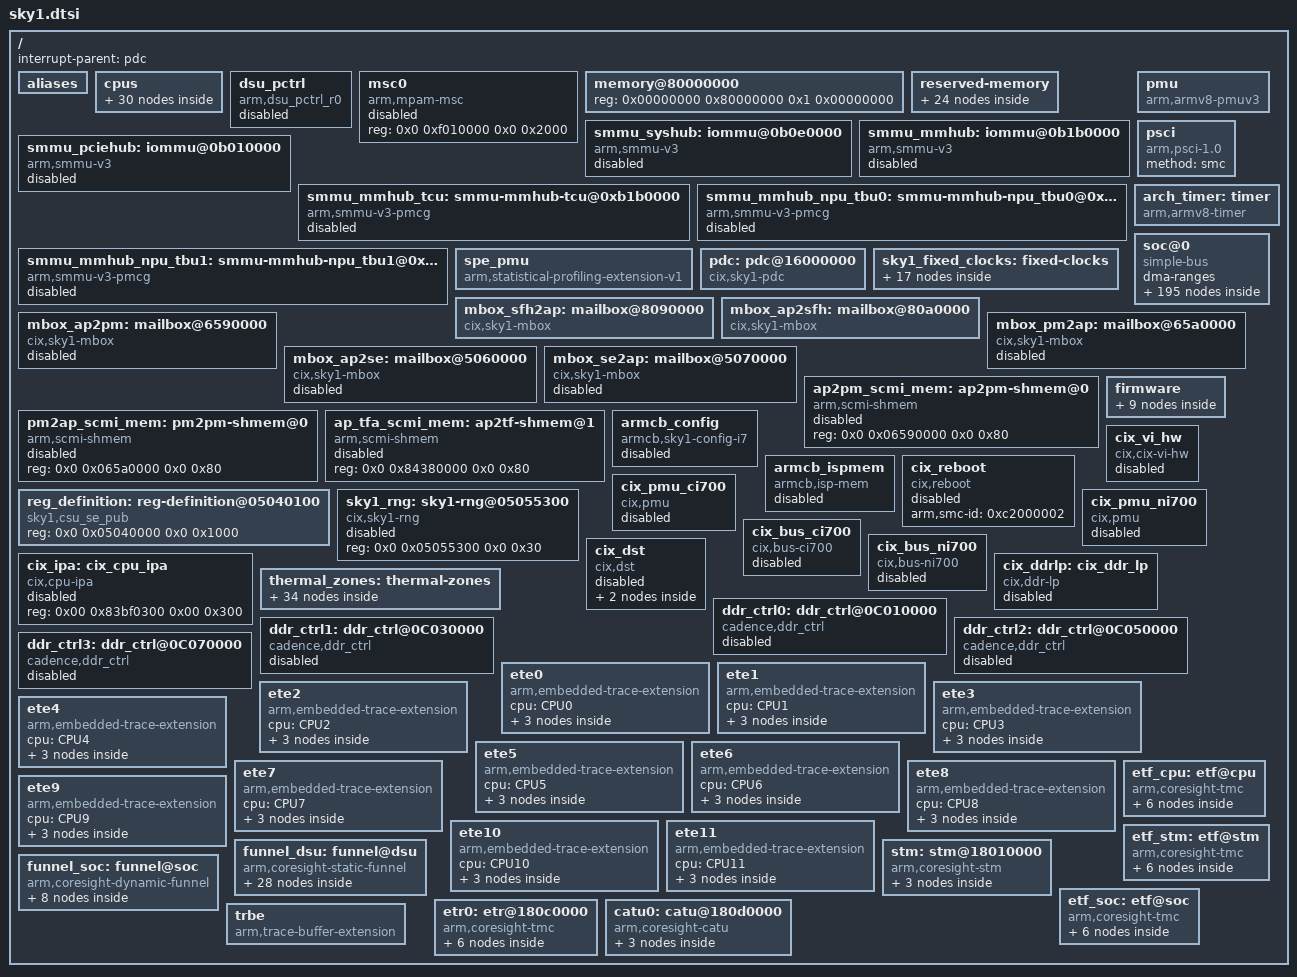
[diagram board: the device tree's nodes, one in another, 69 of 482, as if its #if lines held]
/*
 * Copyright 2024 Cix Technology Group Co., Ltd.
 *
 * SPDX-License-Identifier: BSD-3-Clause
 */

#include <dt-bindings/interrupt-controller/arm-gic.h>
#include <dt-bindings/clock/sky1-audss.h>
#include <dt-bindings/phy/phy.h>
#include <dt-bindings/phy/phy-cadence-torrent.h>
#include <dt-bindings/thermal/thermal.h>
#include <dt-bindings/power/sky1-power.h>
#include <dt-bindings/reset/sky1-reset.h>
#include <dt-bindings/clock/sky1-clk.h>
#include <dt-bindings/thermal/sky1-thermal.h>
#include <dt-bindings/reset/sky1-reset-fch.h>
#include <dt-bindings/reset/sky1-reset-audss.h>
#include <dt-bindings/gpio/gpio.h>
#include <dt-bindings/pinctrl/pads-sky1.h>

/memreserve/ 0x80000000 0x6000000;

/ {
	interrupt-parent = <&pdc>;
	#address-cells = <2>;
	#size-cells = <2>;

	aliases {
		serial0 = &uart0;
		serial1 = &uart1;
		serial2 = &uart2;
		serial3 = &uart3;
		serial4 = &uart4;
		serial5 = &uart5;
		cix-bridge0 = &cix_bridge_0;
		cix-bridge1 = &cix_bridge_1;
		cix-bridge2 = &cix_bridge_2;
		cix-bridge3 = &cix_bridge_3;
		cix-csi0 = &cix_mipi_csi_0;
		cix-csi1 = &cix_mipi_csi_1;
		cix-csi2 = &cix_mipi_csi_2;
		cix-csi3 = &cix_mipi_csi_3;
		cix-dphy0 = &cix_dphy_0;
		cix-dphy1 = &cix_dphy_1;
		cix-dphy2 = &cix_dphy_2;
		cix-dphy3 = &cix_dphy_3;
		cix-dphy4 = &cix_dphy_4;
		cix-dphy5 = &cix_dphy_5;
		cix-dphy-hw0 = &cix_dphy_hw_0;
		cix-dphy-hw1 = &cix_dphy_hw_1;
		pcie_rc0 = &pcie_x8_rc;
		pcie_rc1 = &pcie_x4_rc;
		pcie_rc2 = &pcie_x2_rc;
		pcie_rc3 = &pcie_x1_1_rc;
		pcie_rc4 = &pcie_x1_0_rc;
		i2s0 = &i2s0;
		i2s1 = &i2s1;
		i2s2 = &i2s2;
		i2s3 = &i2s3;
		i2s4 = &i2s4;
		i2s5 = &i2s5;
		i2s6 = &i2s6;
		i2s7 = &i2s7;
		i2s8 = &i2s8;
		i2s9 = &i2s9;
		usb0 = &sky1_usbss_0;
		usb1 = &sky1_usbss_1;
		usb2 = &sky1_usbss_2;
		usb3 = &sky1_usbss_3;
		usb4 = &sky1_usbss_4;
		usb5 = &sky1_usbss_5;
		usb6 = &sky1_usbhs_0;
		usb7 = &sky1_usbhs_1;
		usb8 = &sky1_usbhs_2;
		usb9 = &sky1_usbhs_3;
		usbdpphy0 = &usbc_phy0;
		usbdpphy1 = &usbc_phy1;
		usbdpphy2 = &usbc_phy2;
		usbdpphy3 = &usbc_phy3;
		i2c0 = &i2c0;
		i2c1 = &i2c1;
		i2c2 = &i2c2;
		i2c3 = &i2c3;
		i2c4 = &i2c4;
		i2c5 = &i2c5;
		i2c6 = &i2c6;
		i2c7 = &i2c7;
		i2c8 = &sf_i2c0;
		i2c9 = &sf_i2c1;
		i2c10 = &i2c2_slave;
		i3c0 = &i3c0;
		i3c1 = &i3c1;
		i3c2 = &sf_i3c0;
		i3c3 = &sf_i3c1;
		spi0 = &spi0;
		spi1 = &spi1;
		spi2 = &sf_spi;
		gpio0 = &s5_gpio0;
		gpio1 = &s5_gpio1;
		gpio2 = &s5_gpio2;
		gpio3 = &fch_gpio0;
		gpio4 = &fch_gpio1;
		gpio5 = &fch_gpio2;
		gpio6 = &fch_gpio3;
		linlondp0 = &dpu0;
		linlondp1 = &dpu1;
		linlondp2 = &dpu2;
		linlondp3 = &dpu3;
		linlondp4 = &dpu4;
	};

	cpus {
		#address-cells = <2>;
		#size-cells = <0>;

		cpu-map {
			cluster0 {
				core0 {
					cpu = <&CPU0>;
				};
				core1 {
					cpu = <&CPU1>;
				};
				core2 {
					cpu = <&CPU2>;
				};
				core3 {
					cpu = <&CPU3>;
				};
				core4 {
					cpu = <&CPU4>;
				};
				core5 {
					cpu = <&CPU5>;
				};
				core6 {
					cpu = <&CPU6>;
				};
				core7 {
					cpu = <&CPU7>;
				};
				core8 {
					cpu = <&CPU8>;
				};
				core9 {
					cpu = <&CPU9>;
				};
				core10 {
					cpu = <&CPU10>;
				};
				core11 {
					cpu = <&CPU11>;
				};
			};
		};

		idle-states {
			CPU_SLEEP_0: cpu-sleep-0 {
				compatible = "arm,idle-state";
				arm,psci-suspend-param = <0x0010000>;
				local-timer-stop;
				entry-latency-us = <34>;
				exit-latency-us = <100>;
				min-residency-us = <3000>;
			};

			CPU_SLEEP_1: cpu-sleep-1 {
				compatible = "arm,idle-state";
				arm,psci-suspend-param = <0x10000>;
				local-timer-stop;
				entry-latency-us = <31>;
				exit-latency-us = <79>;
				min-residency-us = <3000>;
			};

			CLUSTER_SLEEP_0: cluster-sleep-0 {
				compatible = "arm,idle-state";
				arm,psci-suspend-param = <0x1010000>;
				local-timer-stop;
				entry-latency-us = <41>;
				exit-latency-us = <104>;
				min-residency-us = <4000>;
			};
		};

		CPU0: cpu0@0 {
			compatible = "arm,armv8";
			reg = <0x0 0x0>;
			device_type = "cpu";
			enable-method = "psci";
			clocks = <&scmi_dvfs 2>;
			#cooling-cells = <2>;
			cpu-idle-states = <&CPU_SLEEP_0 &CLUSTER_SLEEP_0>;
			capacity-dmips-mhz = <403>;
		};

		CPU1: cpu1@100 {
			compatible = "arm,armv8";
			reg = <0x0 0x100>;
			device_type = "cpu";
			enable-method = "psci";
			clocks = <&scmi_dvfs 2>;
			#cooling-cells = <2>;
			cpu-idle-states = <&CPU_SLEEP_0 &CLUSTER_SLEEP_0>;
			capacity-dmips-mhz = <403>;
		};

		CPU2: cpu2@200 {
			compatible = "arm,armv8";
			reg = <0x0 0x200>;
			device_type = "cpu";
			enable-method = "psci";
			clocks = <&scmi_dvfs 2>;
			#cooling-cells = <2>;
			cpu-idle-states = <&CPU_SLEEP_0 &CLUSTER_SLEEP_0>;
			capacity-dmips-mhz = <403>;
		};

		CPU3: cpu3@300 {
			compatible = "arm,armv8";
			reg = <0x0 0x300>;
			device_type = "cpu";
			enable-method = "psci";
			clocks = <&scmi_dvfs 2>;
			#cooling-cells = <2>;
			cpu-idle-states = <&CPU_SLEEP_0 &CLUSTER_SLEEP_0>;
			capacity-dmips-mhz = <403>;
		};

		CPU4: cpu4@400 {
			compatible = "arm,armv8";
			reg = <0x0 0x400>;
			device_type = "cpu";
			enable-method = "psci";
			clocks = <&scmi_dvfs 5>;
			#cooling-cells = <2>;
			cpu-idle-states = <&CPU_SLEEP_1 &CLUSTER_SLEEP_0>;
			capacity-dmips-mhz = <1024>;
		};

		CPU5: cpu5@500 {
			compatible = "arm,armv8";
			reg = <0x0 0x500>;
			device_type = "cpu";
			enable-method = "psci";
			clocks = <&scmi_dvfs 5>;
			#cooling-cells = <2>;
			cpu-idle-states = <&CPU_SLEEP_1 &CLUSTER_SLEEP_0>;
			capacity-dmips-mhz = <1024>;
		};

		CPU6: cpu6@600 {
			compatible = "arm,armv8";
			reg = <0x0 0x600>;
			device_type = "cpu";
			enable-method = "psci";
			clocks = <&scmi_dvfs 6>;
			#cooling-cells = <2>;
			cpu-idle-states = <&CPU_SLEEP_1 &CLUSTER_SLEEP_0>;
			capacity-dmips-mhz = <1024>;
		};

		CPU7: cpu7@700 {
			compatible = "arm,armv8";
			reg = <0x0 0x700>;
			device_type = "cpu";
			enable-method = "psci";
			clocks = <&scmi_dvfs 6>;
			#cooling-cells = <2>;
			cpu-idle-states = <&CPU_SLEEP_1 &CLUSTER_SLEEP_0>;
			capacity-dmips-mhz = <1024>;
		};

		CPU8: cpu8@800 {
			compatible = "arm,armv8";
			reg = <0x0 0x800>;
			device_type = "cpu";
			enable-method = "psci";
			clocks = <&scmi_dvfs 3>;
			#cooling-cells = <2>;
			cpu-idle-states = <&CPU_SLEEP_1 &CLUSTER_SLEEP_0>;
			capacity-dmips-mhz = <1024>;
		};

		CPU9: cpu9@900 {
			compatible = "arm,armv8";
			reg = <0x0 0x900>;
			device_type = "cpu";
			enable-method = "psci";
			clocks = <&scmi_dvfs 3>;
			#cooling-cells = <2>;
			cpu-idle-states = <&CPU_SLEEP_1 &CLUSTER_SLEEP_0>;
			capacity-dmips-mhz = <1024>;
		};

		CPU10: cpu10@a00 {
			compatible = "arm,armv8";
			reg = <0x0 0xa00>;
			device_type = "cpu";
			enable-method = "psci";
			clocks = <&scmi_dvfs 4>;
			#cooling-cells = <2>;
			cpu-idle-states = <&CPU_SLEEP_1 &CLUSTER_SLEEP_0>;
			capacity-dmips-mhz = <1024>;
		};

		CPU11: cpu11@b00 {
			compatible = "arm,armv8";
			reg = <0x0 0xb00>;
			device_type = "cpu";
			enable-method = "psci";
			clocks = <&scmi_dvfs 4>;
			#cooling-cells = <2>;
			cpu-idle-states = <&CPU_SLEEP_1 &CLUSTER_SLEEP_0>;
			capacity-dmips-mhz = <1024>;
		};
	};

	dsu_pctrl: dsu_pctrl {
		compatible = "arm,dsu_pctrl_r0";
		size = <8192>; /* size in KB */
		line-size = <64>;
		static-leakage-per-mb = <10000>; /*uW/MB */
		dram-energy-per-mb = <130>; /* uJ/MB */
		polling = <10000>; /* miliseconds */
		/* hw-automatic-control; */
		/* cluster-l3-dn-th0 = <100>; */
		/* cluster-l3-dn-th1 = <200>; */
		/* cluster-l3-up-th0 = <300>; */
		/* cluster-l3-up-th1 = <400>; */
		/* cluster-l3-up-th2 = <500>; */
		/* cluster-l3-auto-interval = <5>; */ /* IMP_CLUSTERPWRCTLR_EL1.AUTOPRTN */
		status = "disabled";
	};

	/*
	 * L3 cache in the DSU is the Memory System Component (MSC)
	 * The MPAM registers are accessed through utility bus in the DSU
	 */
	msc0 {
		compatible = "arm,mpam-msc";
		reg = <0x0 0xf010000 0x0 0x2000>;
		status = "disabled";
	};

	memory@80000000 {
		#address-cells = <2>;
		#size-cells = <2>;
		device_type = "memory";
		reg = <0x00000000 0x80000000 0x1 0x00000000>;
	};

	reserved-memory {
		#address-cells = <2>;
		#size-cells = <2>;
		ranges;

		linux,cma {
			compatible = "shared-dma-pool";
			reusable;
			size = <0x0 0x28000000>;
			linux,cma-default;
		};

		dpu_gop: dpu_gop@84800000 {
			reg = <0x0 0x84800000 0x0 0x2000000>;
			iommu-addresses = <&dpu0 0x0 0x84800000 0x0 0x02000000>,
				<&dpu1 0x0 0x84800000 0x0 0x02000000>,
				<&dpu2 0x0 0x84800000 0x0 0x02000000>,
				<&dpu3 0x0 0x84800000 0x0 0x02000000>,
				<&dpu4 0x0 0x84800000 0x0 0x02000000>;
			status = "disabled"; /* not for device dma and cma memory */
			no-map;
		};

		smc_shmem_reserved: smc_shmem@84380000 {
			reg = <0x0 0x84380000 0x0 0x80000>;
			no-map;
		};

		smc_shmem_tee_reserved: smc_shmem@82500000 {
			reg = <0x0 0x82500000 0x0 0xb00000>;
			no-map;
		};

		ramoops: cix_ramoops@83d00000 {
			compatible = "ramoops";
			reg = <0x0 0x83d00000 0x0 0x000a0000>;
			record-size = <0x10000>;
			console-size = <0x10000>;
			pmsg-size = <0x1000>;
			status = "disabled";
		};

		mntndump: mntndump@83de0000 {
			compatible = "cix-dst,mntndump";
			no-map;
			reg = <0 0x83de0000 0 0x00020000>;
			status = "disabled";
		};

		rdr_res_region: rdr@83000000 {
			reg = <0 0x83000000 0 0x400000>;
			no-map;
		};

		sfh_vdev0vring0: vdev0vring0@84000000 {
			reg = <0x0 0x84000000 0x0 0x4000>;	/* 16k for vring0 */
			no-map;
		};

		sfh_vdev0vring1: vdev0vring1@84004000 {
			reg = <0x0 0x84004000 0x0 0x4000>;	/* 16k for vring1 */
			no-map;
		};

		sfh_vdev0buffer: vdev0buffer@84008000 {		/* 1M for tx/rx buffer */
			compatible = "shared-dma-pool";
			reg = <0x0 0x84008000 0x0 0x100000>;
			no-map;
		};

		sfh_sharebuffer: sfh_sharebuffer@84800000 {
			reg = <0x0 0x84800000 0x0 0x800000>; /* 8M for IPC */
			no-map;
		};

		sfh_ram: ram0@1ca0000000 {	/* 512KB RAM */
			reg = <0x1c 0xa0000000 0x0 0x80000>;
			no-map;
		};

		aipu_res_0: memory@90000000 {
			compatible = "shared-dma-pool";
			no-map;
			reg = <0x0 0x90000000 0x0 0x20000000>;
		};

		mali_protected: mali_protected@bce00000 {
			compatible = "mali-reserved";
			reg = <0x0 0xbce00000 0x0 0x1000000>;
		};

		vpu_private: vpu_private {
			reg = <0x0 0xbde00000 0x0 0x800000>;
			no-map;
			status = "disabled";
		};

		vpu_protected: vpu_protected {
			reg = <0x0 0xbe600000 0x0 0x1800000>;
			no-map;
			status = "disabled";
		};

		media_protected: media_protected {
			reg = <0x0 0xbfe00000 0x0 0xe000000>;
			no-map;
			status = "disabled";
		};

		dsp_vdev0vring0: vdev0vring0@cde00000 {
			reg = <0x0 0xcde00000 0x0 0x4000>;	/* 16k for vring0 */
			no-map;
		};

		dsp_vdev0vring1: vdev0vring1@cde04000 {
			reg = <0x0 0xcde04000 0x0 0x4000>;	/* 16k for vring1 */
			no-map;
		};

		dsp_vdev0buffer: vdev0buffer@cde08000 {		/* 1M for tx/rx buffer */
			compatible = "shared-dma-pool";
			reg = <0x0 0xcde08000 0x0 0x100000>;
			no-map;
		};

		dsp_reserved: dsp_reserved {
			reg = <0x0 0xce000000 0x0 0x1000000>;
			no-map;
		};

		dsp_reserved_heap: dsp_reserved_heap {
			reg = <0x0 0xcf000000 0x0 0x1000000>;
			no-map;
		};

		audio_alsa: audio_alsa@d0000000 {
			compatible = "shared-dma-pool";
			reg = <0x0 0xd0000000 0x0 0xc00000>;
			no-map;
		};

		audio_alsa_hda: audio_alsa_hda@d0c00000 {
			compatible = "shared-dma-pool";
			reg = <0x0 0xd0c00000 0x0 0x200000>;
			no-map;
		};

	};

	smmu_syshub: iommu@0b0e0000 {
		compatible = "arm,smmu-v3";
		reg = <0 0x0b0e0000 0x0 0xc0000>;
		#iommu-cells = <1>;
		interrupts = <GIC_SPI 90 IRQ_TYPE_EDGE_RISING>,
			<GIC_SPI 99 IRQ_TYPE_EDGE_RISING>,
			<GIC_SPI 91 IRQ_TYPE_EDGE_RISING>,
			<GIC_SPI 95 IRQ_TYPE_EDGE_RISING>;
		interrupt-names = "eventq", "priq", "cmdq-sync", "gerror";
		status = "disabled";
	};

	smmu_mmhub: iommu@0b1b0000 {
		compatible = "arm,smmu-v3";
		reg = <0 0x0b1b0000 0x0 0x400000>;
		#iommu-cells = <1>;
		interrupts = <GIC_SPI 109 IRQ_TYPE_EDGE_RISING>,
			<GIC_SPI 118 IRQ_TYPE_EDGE_RISING>,
			<GIC_SPI 110 IRQ_TYPE_EDGE_RISING>,
			<GIC_SPI 114 IRQ_TYPE_EDGE_RISING>;
		interrupt-names = "eventq", "priq", "cmdq-sync", "gerror";
		status = "disabled";
	};

	smmu_pciehub: iommu@0b010000 {
		compatible = "arm,smmu-v3";
		reg = <0 0x0b010000 0x0 0xc0000>;
		#iommu-cells = <1>;
		interrupts = <GIC_SPI 75 IRQ_TYPE_EDGE_RISING>,
			<GIC_SPI 84 IRQ_TYPE_EDGE_RISING>,
			<GIC_SPI 76 IRQ_TYPE_EDGE_RISING>,
			<GIC_SPI 80 IRQ_TYPE_EDGE_RISING>;
		interrupt-names = "eventq", "priq", "cmdq-sync", "gerror";
		status = "disabled";
	};

	smmu_mmhub_tcu: smmu-mmhub-tcu@0xb1b0000 {
		compatible = "arm,smmu-v3-pmcg";	/* smmu mmhub tcu pmu */
		reg = <0x0 0xb1b2000 0x0 0x1000>,
			<0x0 0xb1d2000 0x0 0x1000>;
		interrupts = <GIC_SPI 117 IRQ_TYPE_EDGE_RISING>;
		interrupt-names = "SMMU_MMHUB TCU";
		status = "disabled";
	};

	smmu_mmhub_npu_tbu0: smmu-mmhub-npu_tbu0@0xb3d0000 {
		compatible = "arm,smmu-v3-pmcg";	/* smmu mmhub npu tbu0 pmu */
		reg = <0x0 0xb3d2000 0x0 0x1000>,
			<0x0 0xb3e2000 0x0 0x1000>;
		interrupts = <GIC_SPI 182 IRQ_TYPE_EDGE_RISING>;
		interrupt-names = "SMMU_MMHUB NPU TBU0";
		status = "disabled";
	};

	smmu_mmhub_npu_tbu1: smmu-mmhub-npu_tbu1@0xb3f0000 {
		compatible = "arm,smmu-v3-pmcg";	/* smmu mmhub npu tbu1 pmu */
		reg = <0x0 0xb3f2000 0x0 0x1000>,
			<0x0 0xb402000 0x0 0x100>;
		interrupts = <GIC_SPI 186 IRQ_TYPE_EDGE_RISING>;
		interrupt-names = "SMMU_MMHUB NPU TBU1";
		status = "disabled";
	};

	pmu: pmu {
		compatible = "arm,armv8-pmuv3";
		interrupts = <GIC_PPI 7 IRQ_TYPE_LEVEL_LOW>;
		interrupt-parent = <&gic>;
		status = "okay";
	};

	spe_pmu: spe_pmu {
		compatible = "arm,statistical-profiling-extension-v1";
		interrupts = <GIC_PPI 5 IRQ_TYPE_LEVEL_LOW>;
		interrupt-parent = <&gic>;
		status = "okay";
	};

	psci {
		compatible = "arm,psci-1.0";
		method = "smc";
	};

	pdc: pdc@16000000 {
		compatible = "cix,sky1-pdc", "syscon";
		reg = <0x0 0x16000000 0x0 0x1000>;
		interrupt-controller;
		#interrupt-cells = <3>;
		interrupt-parent = <&gic>;
	};

	arch_timer: timer {
		compatible = "arm,armv8-timer";
		interrupts = <GIC_PPI 13 IRQ_TYPE_LEVEL_LOW>,
			     <GIC_PPI 14 IRQ_TYPE_LEVEL_LOW>,
			     <GIC_PPI 11 IRQ_TYPE_LEVEL_LOW>,
			     <GIC_PPI 10 IRQ_TYPE_LEVEL_LOW>;
		clock-frequency = <1000000000>;
		interrupt-parent = <&gic>;
		arm,no-tick-in-suspend;
#ifdef CONFIG_ARCH_CIX_EMU_FPGA
		always-on; /* only on EMU/FPGA */
#endif
	};

	sky1_fixed_clocks: fixed-clocks {
		i2cclk: i2cclk {
			compatible = "fixed-clock";
			#clock-cells = <0>;
			clock-frequency = <200000000>;
			clock-output-names = "i2cclk";
		};

		spi_ref_clk: spi_ref_clk {
			compatible = "fixed-clock";
			#clock-cells = <0>;
			clock-frequency = <200000000>;
			clock-output-names = "spi_ref_clk";
		};

		spi_apb_pclk: spi_apb_pclk {
			compatible = "fixed-clock";
			#clock-cells = <0>;
			clock-frequency = <200000000>;
			clock-output-names = "spi_apb_pclk";
		};

		uartclk: uartclk {
			compatible = "fixed-clock";
			#clock-cells = <0>;
			clock-frequency = <100000000>;
			clock-output-names = "uartclk";
		};

		uart_apb_pclk: uart_apb_pclk {
			compatible = "fixed-clock";
			#clock-cells = <0>;
			clock-frequency = <200000000>;
			clock-output-names = "apb_pclk";
		};

		i3c_apb_clk: i3c_apb_clk {
			compatible = "fixed-clock";
			#clock-cells = <0>;
			clock-frequency = <200000000>;
			clock-output-names = "i3c_apb_clk";
		};

		i3c_sys_clk: i3c_sys_clk {
			compatible = "fixed-clock";
			#clock-cells = <0>;
			clock-frequency = <200000000>;
			clock-output-names = "i3c_sys_clk";
		};

		xspi_maclk: xspi_maclk {
			compatible = "fixed-clock";
			#clock-cells = <0>;
			clock-frequency = <200000000>;
			clock-output-names = "xspi_maclk";
		};

		xspi_pclk: xspi_pclk {
			compatible = "fixed-clock";
			#clock-cells = <0>;
			clock-frequency = <200000000>;
			clock-output-names = "xspi_apb_pclk";
		};

		xspi_funcclk: xspi_funcclk {
			compatible = "fixed-clock";
			#clock-cells = <0>;
			clock-frequency = <200000000>;
			clock-output-names = "xspi_funcclk";
		};

		dma_axi_clk: dma_axi_clk {
			compatible = "fixed-clock";
			#clock-cells = <0>;
			clock-frequency = <200000000>;
			clock-output-names = "dma_axi_clk";
		};

		dma_apb_pclk: dma_apb_pclk {
			compatible = "fixed-clock";
			#clock-cells = <0>;
			clock-frequency = <200000000>;
			clock-output-names = "dma_apb_pclk";
		};

		dfd_clk: dummyclk {
			compatible = "fixed-clock";
			clock-frequency = <800000000>;
			#clock-cells = <0>;
		};

		fch_timer_apb_clk: fch_timer_apb_clk {
			compatible = "fixed-clock";
			#clock-cells = <0>;
			clock-frequency = <200000000>;
			clock-output-names = "fch_timer_apb_clk";
		};

		fch_timer_func_clk: fch_timer_func_clk {
			compatible = "fixed-clock";
			#clock-cells = <0>;
			clock-frequency = <25000000>;
			clock-output-names = "fch_timer_func_pclk";
		};

		s5_gpio_apb_clk: s5_gpio_apb_clk {
			compatible = "fixed-clock";
			#clock-cells = <0>;
			clock-frequency = <100000000>;
			clock-output-names = "s5_gpio_apb_clk";
		};

		fch_gpio_apb_clk: fch_gpio_apb_clk {
			compatible = "fixed-clock";
			#clock-cells = <0>;
			clock-frequency = <200000000>;
			clock-output-names = "fch_gpio_apb_clk";
		};
	};

	soc@0 {
		compatible = "simple-bus";
		#address-cells = <2>;
		#size-cells = <2>;
		ranges;
		dma-ranges;

		i2c0: i2c@04010000 {
			#address-cells = <1>;
			#size-cells = <0>;
			compatible = "cdns,i2c-r1p14";
			reg = <0x0 0x04010000 0x0 0x10000>;
			clock-frequency = <400000>;
			clocks = <&scmi_clk CLK_TREE_FCH_I2C0_APB>;
			resets = <&src_fch SW_I2C0_RST_APB_N>;
			reset-names = "i2c_reset";
			interrupts = <GIC_SPI 286 IRQ_TYPE_LEVEL_HIGH>;
			status = "disabled";
		};

		i2c1: i2c@04020000 {
			#address-cells = <1>;
			#size-cells = <0>;
			compatible = "cdns,i2c-r1p14";
			reg = <0x0 0x04020000 0x0 0x10000>;
			clock-frequency = <400000>;
            		clocks = <&scmi_clk CLK_TREE_FCH_I2C1_APB>;
			resets = <&src_fch SW_I2C1_RST_APB_N>;
			reset-names = "i2c_reset";
			interrupts = <GIC_SPI 287 IRQ_TYPE_LEVEL_HIGH>;
			status = "disabled";
		};

		i2c2: i2c@04030000 {
			 #address-cells = <1>;
			 #size-cells = <0>;
			compatible = "cdns,i2c-r1p14";
			reg = <0x0 0x04030000 0x0 0x10000>;
			clock-frequency = <400000>;
            		clocks = <&scmi_clk CLK_TREE_FCH_I2C2_APB>;
			resets = <&src_fch SW_I2C2_RST_APB_N>;
			reset-names = "i2c_reset";
			interrupts = <GIC_SPI 288 IRQ_TYPE_LEVEL_HIGH>;
			status = "disabled";
		};

		i2c2_slave: i2c_slave@04030000 {
			#address-cells = <1>;
			#size-cells = <0>;
			compatible = "cdns,i2c-r1p14";
			reg = <0x0 0x04030000 0x0 0x10000>;
			clock-frequency = <400000>;
            		clocks = <&scmi_clk CLK_TREE_FCH_I2C2_APB>;
			resets = <&src_fch SW_I2C2_RST_APB_N>;
			reset-names = "i2c_reset";
			interrupts = <GIC_SPI 288 IRQ_TYPE_LEVEL_HIGH>;
			status = "disabled";
		};

		i2c3: i2c@04040000 {
			#address-cells = <1>;
			#size-cells = <0>;
			compatible = "cdns,i2c-r1p14";
			reg = <0x0 0x04040000 0x0 0x10000>;
			 clock-frequency = <400000>;
            		clocks = <&scmi_clk CLK_TREE_FCH_I2C3_APB>;
			resets = <&src_fch SW_I2C3_RST_APB_N>;
			reset-names = "i2c_reset";
			interrupts = <GIC_SPI 289 IRQ_TYPE_LEVEL_HIGH>;
			status = "disabled";
		};

		i2c4: i2c@04050000 {
			#address-cells = <1>;
			#size-cells = <0>;
			compatible = "cdns,i2c-r1p14";
			reg = <0x0 0x04050000 0x0 0x10000>;
			clock-frequency = <400000>;
            		clocks = <&scmi_clk CLK_TREE_FCH_I2C4_APB>;
			resets = <&src_fch SW_I2C4_RST_APB_N>;
			reset-names = "i2c_reset";
			interrupts = <GIC_SPI 290 IRQ_TYPE_LEVEL_HIGH>;
			status = "disabled";
		};

		i2c5: i2c@04060000 {
			#address-cells = <1>;
			#size-cells = <0>;
			compatible = "cdns,i2c-r1p14";
			reg = <0x0 0x04060000 0x0 0x10000>;
			clock-frequency = <400000>;
            		clocks = <&scmi_clk CLK_TREE_FCH_I2C5_APB>;
			resets = <&src_fch SW_I2C5_RST_APB_N>;
			reset-names = "i2c_reset";
			interrupts = <GIC_SPI 291 IRQ_TYPE_LEVEL_HIGH>;
			status = "disabled";
		};

		i2c6: i2c@04070000 {
			#address-cells = <1>;
			#size-cells = <0>;
			compatible = "cdns,i2c-r1p14";
			reg = <0x0 0x04070000 0x0 0x10000>;
			clock-frequency = <400000>;
            		clocks = <&scmi_clk CLK_TREE_FCH_I2C6_APB>;
			resets = <&src_fch SW_I2C6_RST_APB_N>;
			reset-names = "i2c_reset";
			interrupts = <GIC_SPI 292 IRQ_TYPE_LEVEL_HIGH>;
			status = "disabled";
		};

		i2c7: i2c@04080000 {
			#address-cells = <1>;
			#size-cells = <0>;
			compatible = "cdns,i2c-r1p14";
			reg = <0x0 0x04080000 0x0 0x10000>;
			clock-frequency = <400000>;
            		clocks = <&scmi_clk CLK_TREE_FCH_I2C7_APB>;
			resets = <&src_fch SW_I2C7_RST_APB_N>;
			reset-names = "i2c_reset";
			interrupts = <GIC_SPI 293 IRQ_TYPE_LEVEL_HIGH>;
			status = "disabled";
		};

		spi0: spi@04090000 {
			#address-cells = <1>;
			#size-cells = <0>;
			compatible = "cdns,spi-r1p6";
			reg = <0x0 0x04090000 0x0 0x10000>;
			clocks = <&scmi_clk CLK_TREE_FCH_SPI0_APB>,
						<&scmi_clk CLK_TREE_FCH_SPI0_APB>;
			clock-names = "pclk", "ref_clk";
			resets = <&src_fch SW_SPI0_RST_APB_N>;
			reset-names = "spi_reset";
			interrupts = <GIC_SPI 294 IRQ_TYPE_LEVEL_HIGH>;
			fifo-width = <32>;
			status = "disabled";
		};

		spi1: spi@040a0000 {
			 #address-cells = <1>;
			#size-cells = <0>;
			compatible = "cdns,spi-r1p6";
			reg = <0x0 0x040a0000 0x0 0x10000>;
			clocks = <&scmi_clk CLK_TREE_FCH_SPI1_APB>,
						<&scmi_clk CLK_TREE_FCH_SPI1_APB>;
			clock-names = "pclk", "ref_clk";
			resets = <&src_fch SW_SPI1_RST_APB_N>;
			reset-names = "spi_reset";
			interrupts = <GIC_SPI 295 IRQ_TYPE_LEVEL_HIGH>;
			fifo-width = <32>;
			status = "disabled";
		};

		uart0: uart@040b0000 {
			compatible = "arm,pl011", "arm,primecell";
			reg = <0x0 0x040b0000 0x0 0x1000>;
			timeout-enable;
			timeout-value = <250000>;
			interrupts = <GIC_SPI 296 IRQ_TYPE_LEVEL_HIGH>;
			clocks = <&scmi_clk CLK_TREE_FCH_UART0_FUNC>, <&scmi_clk CLK_TREE_FCH_UART0_APB>;
			clock-names = "uartclk", "apb_pclk";
			resets = <&src_fch SW_UART0_RST_FUNC_N>, <&src_fch SW_UART0_RST_APB_N>;
			reset-names = "uart_func_reset", "uart_apb_reset";
			status = "disabled";
		};

		uart1: uart@040c0000 {
			compatible = "arm,pl011", "arm,primecell";
			reg = <0x0 0x040c0000 0x0 0x1000>;
			timeout-enable;
			timeout-value = <250000>;
			interrupts = <GIC_SPI 297 IRQ_TYPE_LEVEL_HIGH>;
			clocks = <&scmi_clk CLK_TREE_FCH_UART1_FUNC>, <&scmi_clk CLK_TREE_FCH_UART1_APB>;
			clock-names = "uartclk", "apb_pclk";
			resets = <&src_fch SW_UART1_RST_FUNC_N>, <&src_fch SW_UART1_RST_APB_N>;
			reset-names = "uart_func_reset", "uart_apb_reset";
			status = "disabled";
		};

		uart2: uart@040d0000 {
			compatible = "arm,pl011", "arm,primecell";
			reg = <0x0 0x040d0000 0x0 0x1000>;
			interrupts = <GIC_SPI 298 IRQ_TYPE_LEVEL_HIGH>;
			clocks = <&scmi_clk CLK_TREE_FCH_UART2_FUNC>, <&scmi_clk CLK_TREE_FCH_UART2_APB>;
			clock-names = "uartclk", "apb_pclk";
			status = "disabled";
		};

		uart3: uart@040e0000 {
			compatible = "arm,pl011", "arm,primecell";
			reg = <0x0 0x040e0000 0x0 0x1000>;
			interrupts = <GIC_SPI 299 IRQ_TYPE_LEVEL_HIGH>;
			clocks = <&scmi_clk CLK_TREE_FCH_UART3_FUNC>, <&scmi_clk CLK_TREE_FCH_UART3_APB>;
			clock-names = "uartclk", "apb_pclk";
			status = "disabled";
        	};

		uart4: uart@06540000 {
			compatible = "arm,pl011", "arm,primecell";
			reg = <0x0 0x6540000 0x0 0x1000>;
			status = "disabled";
		};

		uart5: uart@05020000 {
			compatible = "arm,pl011", "arm,primecell";
			reg = <0x0 0x5020000 0x0 0x1000>;
			interrupts = <GIC_SPI 387 IRQ_TYPE_LEVEL_HIGH>;
			status = "disabled";
		};

		i3c0: i3c@040f0000 {
			compatible = "cdns,i3c-master";
			reg = <0x0 0x040f0000 0x0 0x10000>;
			#address-cells = <3>;
			#size-cells = <0>;
			i2c-scl-hz = <100000>;
			interrupts = <GIC_SPI 300 IRQ_TYPE_LEVEL_HIGH>;
			clocks = <&scmi_clk CLK_TREE_FCH_I3C0_APB>, <&scmi_clk CLK_TREE_FCH_I3C0_FUNC>;
			clock-names = "pclk", "sysclk";
			resets = <&src_fch SW_I3C0_RST_FUNC_G_N>, <&src_fch SW_I3C0_RST_FUNC_I_N>, <&src_fch SW_I3C0_RST_APB_N>;
			reset-names = "i3c_funcg","i3c_funci","i3c_apb";
			status = "disabled";
        	};

		i3c1: i3c@04100000 {
			compatible = "cdns,i3c-master";
			reg = <0x0 0x04100000 0x0 0x10000>;
			#address-cells = <3>;
			#size-cells = <0>;
			i2c-scl-hz = <100000>;
			interrupts = <GIC_SPI 301 IRQ_TYPE_LEVEL_HIGH>;
			clocks = <&scmi_clk CLK_TREE_FCH_I3C1_APB>, <&scmi_clk CLK_TREE_FCH_I3C1_FUNC>;
			clock-names = "pclk", "sysclk";
			resets = <&src_fch SW_I3C1_RST_FUNC_G_N>, <&src_fch SW_I3C1_RST_FUNC_I_N>, <&src_fch SW_I3C1_RST_APB_N>;
			reset-names = "i3c_funcg","i3c_funci","i3c_apb";
			status = "disabled";
         	};

                xspi: xspi@04180000 {
			compatible = "cdns,xspi-nor";
			reg = <0x0 0x04180000 0x0 0x10000>, <0x0 0x10000 0x0 0x4000000>;
			reg-names = "io", "sdma";
			#address-cells = <1>;
			#size-cells = <0>;
			interrupts = <GIC_SPI 302 IRQ_TYPE_LEVEL_HIGH>;
			clocks = <&scmi_clk CLK_TREE_FCH_XSPI_APB>, <&scmi_clk CLK_TREE_FCH_XSPI_MACLK>, <&scmi_clk CLK_TREE_FCH_XSPI_FUNC>;
			clock-names = "pclk", "maclk", "funcclk";
			resets = <&src_fch SW_XSPI_SYS_RST_N>, <&src_fch SW_XSPI_REG_RST_N>;
                        reset-names = "xspi_sys_reset", "xspi_reg_reset";
			status = "disabled";
		};

		fch_cru: fch_cru@0x416009c {
			compatible = "sky1,fch_cru", "syscon";
			reg = <0x0 0x0416009c 0x0 0x80>;
		};

		fch_dmac: dma-controller@4190000 {
			compatible = "arm,dma350-full";
			reg = <0x0 0x4190000 0x0 0x10000>;
			#dma-cells = <2>;
			dma-channels = <8>;
        		dma-requests = <8>;
			interrupts = <GIC_SPI 303 IRQ_TYPE_LEVEL_HIGH>;
			clocks = <&scmi_clk CLK_TREE_FCH_DMA_ACLK>;
			clock-names = "axiclk";
			resets = <&src_fch SW_DMA_RST_AXI_N>;
			reset-names = "dma_reset";
			status = "okay";
		};

		csu_se@05000000 {
			compatible = "cix,sky1-se";
			mbox-names = "tx3", "rx3";
			mboxes = <&mbox_ap2se 9>,	/* index=9: fifo base channel */
				 <&mbox_se2ap 9>;
			status = "disabled";
		};

		csu_pm@06000000 {
			compatible = "cix,sky1-pm";
			mbox-names = "tx2", "rx2";
			mboxes = <&mbox_ap2pm 8>,	/* index=8: Reg/DB base channel */
				 <&mbox_pm2ap 8>;
			status = "disabled";
		};

		sf_i2c0: i2c@08030000 {
			#address-cells = <1>;
			#size-cells = <0>;
			compatible = "cdns,i2c-r1p14";
			reg = <0x0 0x08030000 0x0 0x10000>;
			clock-frequency = <400000>;
			clocks = <&i2cclk>;
			interrupts = <GIC_SPI 398 IRQ_TYPE_LEVEL_HIGH>;
			status = "disabled";
		};

		sf_i2c1: i2c@08040000 {
			#address-cells = <1>;
			#size-cells = <0>;
			compatible = "cdns,i2c-r1p14";
			reg = <0x0 0x08040000 0x0 0x10000>;
			clock-frequency = <400000>;
			clocks = <&i2cclk>;
			interrupts = <GIC_SPI 397 IRQ_TYPE_LEVEL_HIGH>;
			status = "disabled";
		};

		sf_spi: spi@08070000 {
			#address-cells = <1>;
			#size-cells = <0>;
			compatible = "cdns,spi-r1p6";
			reg = <0x0 0x08070000 0x0 0x10000>;
			clocks = <&spi_ref_clk>, <&spi_apb_pclk>;
			clock-names = "pclk", "ref_clk";
			interrupts = <GIC_SPI 394 IRQ_TYPE_LEVEL_HIGH>;
			fifo-width = <32>;
			status = "disabled";
		};

		sf_i3c0: i3c@08050000 {
			compatible = "cdns,i3c-master";
			reg = <0x0 0x08050000 0x0 0x10000>;
			#address-cells = <3>;
			#size-cells = <0>;
			i2c-scl-hz = <100000>;
			i3c-scl-hz = <100000>;
			interrupts = <GIC_SPI 396 IRQ_TYPE_LEVEL_HIGH>;
			clocks = <&i3c_apb_clk>, <&i3c_sys_clk>;
			clock-names = "pclk", "sysclk";
			status = "disabled";
	        };

		sf_i3c1: i3c@08060000 {
			compatible = "cdns,i3c-master";
			reg = <0x0 0x08060000 0x0 0x10000>;
			#address-cells = <3>;
			#size-cells = <0>;
			i2c-scl-hz = <100000>;
			interrupts = <GIC_SPI 395 IRQ_TYPE_LEVEL_HIGH>;
			clocks = <&i3c_apb_clk>, <&i3c_sys_clk>;
			clock-names = "pclk", "sysclk";
			status = "disabled";
       		 };

		hifi5: audio-dsp@07000000 {
			compatible = "cix,sky1-hifi5";
			reg = <0x0 0x07000000 0x0 0x1000000>;
			interrupts = <GIC_SPI 229 IRQ_TYPE_LEVEL_HIGH>; /* watchdog interrupt */
			resets = <&src SKY1_AUDIO_HIFI5_RESET_N>,
				 <&audss_rst AUDSS_MB0_SW_RST_N>,
				 <&audss_rst AUDSS_MB1_SW_RST_N>;
			reset-names = "dsp", "mb0", "mb1";
			clocks = <&audss_clk CLK_DSP_CLK>,
				 <&audss_clk CLK_DSP_BCLK>,
				 <&audss_clk CLK_DSP_PBCLK>,
				 <&audss_clk CLK_SRAM_AXI>,
				 <&audss_clk CLK_MB_0_APB>,
				 <&audss_clk CLK_MB_1_APB>;
			clock-names = "clk", "bclk", "pbclk", "sramclk", "mb0clk", "mb1clk";
			firmware-name = "dsp_fw.bin";
			mbox-names = "tx0", "rx0";
			mboxes = <&mbox_ap2dsp 9>,	/* index=9: fifo base channel */
				 <&mbox_dsp2ap 9>;
			cix,dsp-ctrl = <&audss_cru>;
			status = "disabled";
		};

		audss_dmac: dma-controller@07010000 {
			compatible = "arm,dma350-no-pause";
			reg = <0x0 0x07010000 0x0 0x10000>;
			interrupts = <GIC_SPI 230 IRQ_TYPE_LEVEL_HIGH>;
			#dma-cells = <2>;
			dma-channels = <8>;
			dma-requests = <20>;
			clocks = <&audss_clk CLK_DMAC_AXI>;
			clock-names = "axiclk";
			arm,clk-enable-atomic;
			arm,reg-map = <0x07010000 0x20000000>;
			arm,ram-map = <0xc0000000 0x30000000>;
			arm,remote-ctrl = <&audss_cru>;
			resets = <&audss_rst AUDSS_DMAC_SW_RST_N>;
			reset-names = "dma_reset";
			status = "disabled";
		};

		i2s0: i2s@07020000 {
			compatible = "cdns,sky1-i2s-sc";
			reg = <0x0 0x07020000 0x0 0x10000>;
			interrupts = <GIC_SPI 219 IRQ_TYPE_LEVEL_HIGH>;
			clocks = <&audss_clk CLK_I2S0_APB>,
				 <&audss_clk CLK_I2S0>,
				 <&scmi_clk CLK_TREE_AUDIO_CLK0>,
				 <&scmi_clk CLK_TREE_AUDIO_CLK2>;
			clock-names = "hst", "i2s",
				      "audio_clk0", "audio_clk2";
			resets = <&audss_rst AUDSS_I2S0_SW_RST_N>;
			reset-names = "i2s";
			cdns,cru-ctrl = <&audss_cru>;
			#sound-dai-cells = <0>;
			status = "disabled";
		};

		i2s1: i2s@07030000 {
			compatible = "cdns,sky1-i2s-sc";
			reg = <0x0 0x07030000 0x0 0x10000>;
			interrupts = <GIC_SPI 220 IRQ_TYPE_LEVEL_HIGH>;
			clocks = <&audss_clk CLK_I2S1_APB>,
				 <&audss_clk CLK_I2S1>,
				 <&scmi_clk CLK_TREE_AUDIO_CLK0>,
				 <&scmi_clk CLK_TREE_AUDIO_CLK2>;
			clock-names = "hst", "i2s",
				      "audio_clk0", "audio_clk2";
			resets = <&audss_rst AUDSS_I2S1_SW_RST_N>;
			reset-names = "i2s";
			cdns,cru-ctrl = <&audss_cru>;
			#sound-dai-cells = <0>;
			status = "disabled";
		};

		i2s2: i2s@07040000 {
			compatible = "cdns,sky1-i2s-sc";
			reg = <0x0 0x07040000 0x0 0x10000>;
			interrupts = <GIC_SPI 221 IRQ_TYPE_LEVEL_HIGH>;
			clocks = <&audss_clk CLK_I2S2_APB>,
				 <&audss_clk CLK_I2S2>,
				 <&scmi_clk CLK_TREE_AUDIO_CLK0>,
				 <&scmi_clk CLK_TREE_AUDIO_CLK2>;
			clock-names = "hst", "i2s",
				      "audio_clk0", "audio_clk2";
			resets = <&audss_rst AUDSS_I2S2_SW_RST_N>;
			reset-names = "i2s";
			cdns,cru-ctrl = <&audss_cru>;
			#sound-dai-cells = <0>;
			status = "disabled";
		};

		i2s3: i2s@07050000 {
			compatible = "cdns,sky1-i2s-mc";
			reg = <0x0 0x07050000 0x0 0x10000>;
			interrupts = <GIC_SPI 222 IRQ_TYPE_LEVEL_HIGH>;
			clocks = <&audss_clk CLK_I2S3_APB>,
				 <&audss_clk CLK_I2S3>,
				 <&scmi_clk CLK_TREE_AUDIO_CLK0>,
				 <&scmi_clk CLK_TREE_AUDIO_CLK1>,
				 <&scmi_clk CLK_TREE_AUDIO_CLK2>,
				 <&scmi_clk CLK_TREE_AUDIO_CLK3>;
			clock-names = "hst", "i2s",
				      "audio_clk0", "audio_clk1",
				      "audio_clk2", "audio_clk3";
			resets = <&audss_rst AUDSS_I2S3_SW_RST_N>;
			reset-names = "i2s";
			cdns,pin-out-num = /bits/ 8 <6>;
			#sound-dai-cells = <1>;
			status = "disabled";
		};

		i2s4: i2s@07060000 {
			compatible = "cdns,sky1-i2s-mc";
			reg = <0x0 0x07060000 0x0 0x10000>;
			interrupts = <GIC_SPI 223 IRQ_TYPE_LEVEL_HIGH>;
			clocks = <&audss_clk CLK_I2S4_APB>,
				 <&audss_clk CLK_I2S4>,
				 <&scmi_clk CLK_TREE_AUDIO_CLK0>,
				 <&scmi_clk CLK_TREE_AUDIO_CLK1>,
				 <&scmi_clk CLK_TREE_AUDIO_CLK2>,
				 <&scmi_clk CLK_TREE_AUDIO_CLK3>;
			clock-names = "hst", "i2s",
				      "audio_clk0", "audio_clk1",
				      "audio_clk2", "audio_clk3";
			resets = <&audss_rst AUDSS_I2S4_SW_RST_N>;
			reset-names = "i2s";
			cdns,pin-out-num = /bits/ 8 <4>;
			#sound-dai-cells = <1>;
			status = "disabled";
		};

		i2s5: i2s@07070000 {
			compatible = "cdns,sky1-i2s-mc";
			reg = <0x0 0x07070000 0x0 0x10000>;
			interrupts = <GIC_SPI 224 IRQ_TYPE_LEVEL_HIGH>;
			clocks = <&audss_clk CLK_I2S5_APB>,
				 <&audss_clk CLK_I2S5>,
				 <&scmi_clk CLK_TREE_AUDIO_CLK0>,
				 <&scmi_clk CLK_TREE_AUDIO_CLK2>;
			clock-names = "hst", "i2s",
				      "audio_clk0", "audio_clk2";
			resets = <&audss_rst AUDSS_I2S5_SW_RST_N>;
			reset-names = "i2s";
			cdns,pin-out-num = /bits/ 8 <4>;
			#sound-dai-cells = <1>;
			status = "disabled";
		};

		i2s6: i2s@07080000 {
			compatible = "cdns,sky1-i2s-mc";
			reg = <0x0 0x07080000 0x0 0x10000>;
			interrupts = <GIC_SPI 225 IRQ_TYPE_LEVEL_HIGH>;
			clocks = <&audss_clk CLK_I2S6_APB>,
				 <&audss_clk CLK_I2S6>,
				 <&scmi_clk CLK_TREE_AUDIO_CLK0>,
				 <&scmi_clk CLK_TREE_AUDIO_CLK2>;
			clock-names = "hst", "i2s",
				      "audio_clk0", "audio_clk2";
			resets = <&audss_rst AUDSS_I2S6_SW_RST_N>;
			reset-names = "i2s";
			cdns,pin-out-num = /bits/ 8 <4>;
			#sound-dai-cells = <1>;
			status = "disabled";
		};

		i2s7: i2s@07090000 {
			compatible = "cdns,sky1-i2s-mc";
			reg = <0x0 0x07090000 0x0 0x10000>;
			interrupts = <GIC_SPI 226 IRQ_TYPE_LEVEL_HIGH>;
			clocks = <&audss_clk CLK_I2S7_APB>,
				 <&audss_clk CLK_I2S7>,
				 <&scmi_clk CLK_TREE_AUDIO_CLK0>,
				 <&scmi_clk CLK_TREE_AUDIO_CLK2>;
			clock-names = "hst", "i2s",
				      "audio_clk0", "audio_clk2";
			resets = <&audss_rst AUDSS_I2S7_SW_RST_N>;
			reset-names = "i2s";
			cdns,pin-out-num = /bits/ 8 <4>;
			#sound-dai-cells = <1>;
			status = "disabled";
		};

		i2s8: i2s@070a0000 {
			compatible = "cdns,sky1-i2s-mc";
			reg = <0x0 0x070a0000 0x0 0x10000>;
			interrupts = <GIC_SPI 227 IRQ_TYPE_LEVEL_HIGH>;
			clocks = <&audss_clk CLK_I2S8_APB>,
				 <&audss_clk CLK_I2S8>,
				 <&scmi_clk CLK_TREE_AUDIO_CLK0>,
				 <&scmi_clk CLK_TREE_AUDIO_CLK2>;
			clock-names = "hst", "i2s",
				      "audio_clk0", "audio_clk2";
			resets = <&audss_rst AUDSS_I2S8_SW_RST_N>;
			reset-names = "i2s";
			cdns,pin-out-num = /bits/ 8 <4>;
			#sound-dai-cells = <1>;
			status = "disabled";
		};

		i2s9: i2s@070b0000 {
			compatible = "cdns,sky1-i2s-mc";
			reg = <0x0 0x070b0000 0x0 0x10000>;
			interrupts = <GIC_SPI 228 IRQ_TYPE_LEVEL_HIGH>;
			clocks = <&audss_clk CLK_I2S9_APB>,
				 <&audss_clk CLK_I2S9>,
				 <&scmi_clk CLK_TREE_AUDIO_CLK0>,
				 <&scmi_clk CLK_TREE_AUDIO_CLK2>;
			clock-names = "hst", "i2s",
				      "audio_clk0", "audio_clk2";
			resets = <&audss_rst AUDSS_I2S9_SW_RST_N>;
			reset-names = "i2s";
			cdns,pin-out-num = /bits/ 8 <4>;
			#sound-dai-cells = <1>;
			status = "disabled";
		};

		ipb_hda: ipb-hda@070c0000 {
			compatible = "cix,sky1-ipbloq-hda";
			reg = <0x0 0x070c0000 0x0 0x10000>;
			interrupts = <GIC_SPI 234 IRQ_TYPE_LEVEL_HIGH>;
			clocks = <&audss_clk CLK_HDA_SYS>,
				<&audss_clk CLK_HDA_HDA>;
			clock-names = "sysclk", "clk48m";
			resets = <&audss_rst AUDSS_HDA_SW_RST_N>;
			reset-names = "hda";
			status = "disabled";
		};

		mbox_ap2dsp: mailbox@70f0000 {
			compatible = "cix,sky1-mbox";
			reg = <0x0 0x070f0000 0x0 0x10000>;
			interrupts = <GIC_SPI 232 IRQ_TYPE_LEVEL_HIGH>;
			#mbox-cells = <1>;
			cix,mbox_dir = <0>; /* 0:tx; 1:rx */
			status = "disabled";
		};

		mbox_dsp2ap: mailbox@7100000 {
			compatible = "cix,sky1-mbox";
			reg = <0x0 0x07100000 0x0 0x10000>;
			interrupts = <GIC_SPI 233 IRQ_TYPE_LEVEL_HIGH>;
			#mbox-cells = <1>;
			cix,mbox_dir = <1>; /* 0:tx; 1:rx */
			status = "disabled";
		};

		audss_cru: system-controller@07110000 {
			compatible = "cix,audio-ss-cru", "simple-mfd", "syscon";
			reg = <0x0 0x07110000 0x0 0x10000>;
			status = "disabled";

			audss_clk: clock-controller {
				compatible = "cix,sky1-audss-clock";
				power-domains = <&smc_devpd SKY1_PD_AUDIO>;
				power-domain-names = "audio";
				resets = <&src SKY1_AUDIO_HIFI5_NOC_RESET_N>;
				reset-names = "noc";
				clocks = <&scmi_clk CLK_TREE_AUDIO_CLK0>, <&scmi_clk CLK_TREE_AUDIO_CLK1>,
					 <&scmi_clk CLK_TREE_AUDIO_CLK2>, <&scmi_clk CLK_TREE_AUDIO_CLK3>,
					 <&scmi_clk CLK_TREE_AUDIO_CLK4>, <&scmi_clk CLK_TREE_AUDIO_CLK5>;
				clock-names = "audio_clk0", "audio_clk1",
					      "audio_clk2", "audio_clk3",
					      "audio_clk4", "audio_clk5";
				#clock-cells = <1>;
				status = "disabled";
			};

			audss_rst: reset-controller {
				compatible = "cix,sky1-audss-reset";
				#reset-cells = <1>;
				status = "disabled";
			};
		};

		sensorhub: sensor-mcu@08000000 {
			compatible = "cix,sky1-sfh";
			reg = <0x0 0x08000000 0x0 0x1000000>;
			interrupts = <GIC_SPI 393 IRQ_TYPE_LEVEL_HIGH>,
					<GIC_SPI 401 IRQ_TYPE_LEVEL_HIGH>;
			interrupt-names = "wdt","sw_intr";
			firmware-name = "sfh_fw.bin";
			clocks = <&scmi_clk CLK_TREE_S5_SENSOR_HUB_25M>,
				 <&scmi_clk CLK_TREE_S5_SENSOR_HUB_400M>;
			clock-names = "sensor_hub_25M", "sensor_hub_400M";
			resets = <&src SKY1_SENSORHUB_RESET_N>,
				<&src SKY1_SENSORHUB_NOC_RESET_N>;
			reset-names = "reset", "noc_reset";
			mbox-names = "tx1", "rx1";
			mboxes = <&mbox_ap2sfh 9>,	/* index=9: FIFO based channel */
				 <&mbox_sfh2ap 9>;
			cix,sfh-ctrl = <&sfh_cru>;
			wakeup-source;
			status = "disabled";
		};

		sfh_cru: sfh_cru@08080000 {
			compatible = "sky1,sfh_cru", "syscon";
			reg = <0x0 0x08080000 0x0 0x1000>;
		};

		sfh_scp: sfh_scp@08100000 {
			compatible = "cix,sfh_scp";
			status = "disabled";
		};

		cix_se2ap_mbox: cix_se2ap_mbox {
			compatible = "cix,cix_se2ap_mbox";
			mbox-names = "tx4", "rx4";
			mboxes = <&mbox_ap2se 10>, <&mbox_se2ap 9>;  /* index=9: fifo base channel */
			status = "okay";
		};

		sky1_crash: cix_se_pm_crash {
			compatible = "cix,se_pm_crash";
			status = "disabled";
		};

		gmac_rcsu: gmac_rcsu@9310000 {
			compatible = "sky1,gmac_rcsu", "syscon";
			reg = <0x0 0x09310000 0x0 0x1000>;
		};

		macb0: ethernet@9320000 {
				compatible = "cdns,sky1-gem";
				reg = <0x0 0x09320000 0x0 0x10000>;
				iommus = <&smmu_syshub 0xC>;
				interrupts = <GIC_SPI 343 IRQ_TYPE_LEVEL_HIGH>,	/* Queue 0 */
					     <GIC_SPI 344 IRQ_TYPE_LEVEL_HIGH>,	/* Queue 1 */
					     <GIC_SPI 345 IRQ_TYPE_LEVEL_HIGH>,	/* Queue 2 */
					     <GIC_SPI 346 IRQ_TYPE_LEVEL_HIGH>,	/* Queue 3 */
					     <GIC_SPI 347 IRQ_TYPE_LEVEL_HIGH>,	/* Queue 4 */
					     <GIC_SPI 348 IRQ_TYPE_LEVEL_HIGH>,	/* Queue 5 */
					     <GIC_SPI 349 IRQ_TYPE_LEVEL_HIGH>,	/* Queue 6 */
					     <GIC_SPI 350 IRQ_TYPE_LEVEL_HIGH>;	/* Queue 7 */
				clocks = <&scmi_clk CLK_TREE_GMAC0_ACLK>,
					 <&scmi_clk CLK_TREE_GMAC0_PCLK>,
					 <&scmi_clk CLK_TREE_GMAC0_DIV_TXCLK>;
				clock-names = "aclk", "pclk", "tx_clk";
				resets = <&src SKY1_GMAC0_RST_N>;
				reset-names = "gmac_rstn";
				status = "disabled";
		};

		macb1: ethernet@9330000 {
				compatible = "cdns,sky1-gem";
				reg = <0x0 0x09330000 0x0 0x10000>;
				iommus = <&smmu_syshub 0xB>;
				interrupts = <GIC_SPI 351 IRQ_TYPE_LEVEL_HIGH>,	/* Queue 0 */
					     <GIC_SPI 352 IRQ_TYPE_LEVEL_HIGH>,	/* Queue 1 */
					     <GIC_SPI 353 IRQ_TYPE_LEVEL_HIGH>,	/* Queue 2 */
					     <GIC_SPI 354 IRQ_TYPE_LEVEL_HIGH>,	/* Queue 3 */
					     <GIC_SPI 355 IRQ_TYPE_LEVEL_HIGH>,	/* Queue 4 */
					     <GIC_SPI 356 IRQ_TYPE_LEVEL_HIGH>,	/* Queue 5 */
					     <GIC_SPI 357 IRQ_TYPE_LEVEL_HIGH>,	/* Queue 6 */
					     <GIC_SPI 358 IRQ_TYPE_LEVEL_HIGH>;	/* Queue 7 */
				clocks = <&scmi_clk CLK_TREE_GMAC1_ACLK>,
					 <&scmi_clk CLK_TREE_GMAC1_PCLK>,
					 <&scmi_clk CLK_TREE_GMAC1_DIV_TXCLK>;
				clock-names = "aclk", "pclk", "tx_clk";
				resets = <&src SKY1_GMAC1_RST_N>;
				reset-names = "gmac_rstn";
				status = "disabled";
		};

		sky1_usbss_0:usb@9000000 {
			compatible = "cix,sky1-usbssp";
			#address-cells = <2>;
			#size-cells = <2>;
			ranges;
			reg = <0x00 0x09000310 0x00 0x4>,
				<0x00 0x09000400 0x00 0x4>;
			reg-names = "axi_property", "controller_status";
			resets = <&src SKY1_USBC_SS0_PRST_N>,
				<&src SKY1_USBC_SS0_RST_N>;
			reset-names = "usb_preset", "usb_reset";
			clocks = <&scmi_clk CLK_TREE_USB3C_DRD_CLK_SOF>,
				<&scmi_clk CLK_TREE_USB3C_DRD_AXI_GATE>,
				<&scmi_clk CLK_TREE_USB3C_DRD_CLK_LPM>,
				<&scmi_clk CLK_TREE_USB3C_DRD_APB_GATE>;
			clock-names = "sof_clk", "usb_aclk", "lpm_clk", "usb_pclk";
			cix,usb_syscon = <&src>;
			axi_bmax_value = <0x7>;
			status = "disabled";
			usbss_0: usb-controller@9010000 {
				compatible = "cdns,usbssp";
				reg = <0x00 0x9010000 0x00 0x4000>,
						<0x00 0x9014000 0x00 0x4000>,
						<0x00 0x9018000 0x00 0x8000>;
				reg-names = "otg", "dev", "xhci";
				interrupts = <GIC_SPI USB_C_SSP_0_HOST_IRQ IRQ_TYPE_LEVEL_HIGH>,	/* host irq */
						<GIC_SPI USB_C_SSP_0_PERIPHERAL_IRQ IRQ_TYPE_LEVEL_HIGH>,	/* peripheral irq */
						<GIC_SPI USB_C_SSP_0_OTG_IRQ IRQ_TYPE_LEVEL_HIGH>,	/* otgirq */
						<GIC_SPI USB_C_SSP_0_WAKEUP_IRQ IRQ_TYPE_LEVEL_HIGH>;	/* wakeup irq */
				interrupt-names = "host",
						"peripheral",
						"otg",
						"wakeup";
				maximum-speed = "super-speed-plus";
				dr_mode = "otg";
				phys = <&usb3_phy0>;
				phy-names = "cdnsp,usb3-phy";
				status = "disabled";
			};
		};

		usb2_phy4:usb-phy@9020000 {
			compatible = "cix,sky1-usb2-phy";
			resets = <&src SKY1_USBPHY_HS4_PRST_N>;
			reset-names = "preset";
			#phy-cells = <0>;
			status = "disabled";
		};

		usbc_phy0:usb-phy@9030000 {
			#address-cells = <1>;
			#size-cells = <0>;
			compatible = "cix,sky1-usbdp-phy";
			reg = <0x00 0x9030000 0x00 0x40000>;
			status = "disabled";

			resets = <&src SKY1_USB_DP_PHY0_RST_N>,
					<&src SKY1_USB_DP_PHY0_PRST_N>;
			reset-names = "reset", "preset";

			clocks = <&scmi_clk CLK_TREE_USB3C_DRD_PHY3_GATE>;
			clock-names = "pclk";

			cix,usbphy_syscon = <&src>;

			usb3_phy0: usb-port {
				#phy-cells = <0>;
				reg = <0x0>;
				status = "disabled";
			};
			usbc0_dp_phy: dp-port {
				#phy-cells = <0>;
				reg = <0x1>;
				status = "disabled";
			};
		};

		sky1_usbss_1:usb@9070000 {
			compatible = "cix,sky1-usbssp";
			#address-cells = <2>;
			#size-cells = <2>;
			ranges;
			reg = <0x00 0x09070310 0x00 0x4>,
				<0x00 0x09070400 0x00 0x4>;
			reg-names = "axi_property", "controller_status";
			resets = <&src SKY1_USBC_SS1_PRST_N>,
				<&src SKY1_USBC_SS1_RST_N>;
			reset-names = "usb_preset", "usb_reset";
			clocks = <&scmi_clk CLK_TREE_USB3C_H0_CLK_SOF>,
				<&scmi_clk CLK_TREE_USB3C_0_AXI_GATE>,
				<&scmi_clk CLK_TREE_USB3C_H0_CLK_LPM>,
				<&scmi_clk CLK_TREE_USB3C_0_APB_GATE>;
			clock-names = "sof_clk", "usb_aclk", "lpm_clk", "usb_pclk";
			cix,usb_syscon = <&src>;
			axi_bmax_value = <0x7>;
			status = "disabled";
			usbss_1: usb-controller@9080000 {
				compatible = "cdns,usbssp";
				reg = <0x00 0x9080000 0x00 0x4000>,
						<0x00 0x9084000 0x00 0x4000>,
						<0x00 0x9088000 0x00 0x8000>;
				reg-names = "otg", "dev", "xhci";
				interrupts = <GIC_SPI USB_C_SSP_1_HOST_IRQ IRQ_TYPE_LEVEL_HIGH>,	/* host irq */
						<GIC_SPI USB_C_SSP_1_PERIPHERAL_IRQ IRQ_TYPE_LEVEL_HIGH>,	/* peripheral irq */
						<GIC_SPI USB_C_SSP_1_OTG_IRQ IRQ_TYPE_LEVEL_HIGH>,	/* otgirq */
						<GIC_SPI USB_C_SSP_1_WAKEUP_IRQ IRQ_TYPE_LEVEL_HIGH>;	/* wakeup irq */
				interrupt-names = "host",
						"peripheral",
						"otg",
						"wakeup";
				maximum-speed = "super-speed-plus";
				dr_mode = "host";
				phys = <&usb3_phy1>;
				phy-names = "cdnsp,usb3-phy";
				status = "disabled";
			};
		};

		usb2_phy5:usb-phy@9090000 {
			compatible = "cix,sky1-usb2-phy";
			resets = <&src SKY1_USBPHY_HS5_PRST_N>;
			reset-names = "preset";
			#phy-cells = <0>;
			status = "disabled";
		};

		usbc_phy1:usb-phy@90A0000 {
			#address-cells = <1>;
			#size-cells = <0>;
			compatible = "cix,sky1-usbdp-phy";
			reg = <0x00 0x90A0000 0x00 0x40000>;
			status = "disabled";

			resets = <&src SKY1_USB_DP_PHY1_RST_N>,
					<&src SKY1_USB_DP_PHY1_PRST_N>;
			reset-names = "reset", "preset";

			clocks = <&scmi_clk CLK_TREE_USB3C_0_PHY3_GATE>;
			clock-names = "pclk";

			cix,usbphy_syscon = <&src>;

			usb3_phy1: usb-port {
				#phy-cells = <0>;
				reg = <0x0>;
				status = "disabled";
			};
			usbc1_dp_phy: dp-port {
				#phy-cells = <0>;
				reg = <0x1>;
				status = "disabled";
			};
		};

		sky1_usbss_2:usb@90e0000 {
			compatible = "cix,sky1-usbssp";
			#address-cells = <2>;
			#size-cells = <2>;
			ranges;
			reg = <0x00 0x090e0310 0x00 0x4>,
				<0x00 0x090e0400 0x00 0x4>;
			reg-names = "axi_property", "controller_status";
			resets = <&src SKY1_USBC_SS4_PRST_N>,
				<&src SKY1_USBC_SS4_RST_N>;
			reset-names = "usb_preset", "usb_reset";
			clocks = <&scmi_clk CLK_TREE_USB3C_H1_CLK_SOF>,
				<&scmi_clk CLK_TREE_USB3C_1_AXI_GATE>,
				<&scmi_clk CLK_TREE_USB3C_H1_CLK_LPM>,
				<&scmi_clk CLK_TREE_USB3C_1_APB_GATE>;
			clock-names = "sof_clk", "usb_aclk", "lpm_clk", "usb_pclk";
			cix,usb_syscon = <&src>;
			axi_bmax_value = <0x7>;
			status = "disabled";
			usbss_2: usb-controller@90f0000 {
				compatible = "cdns,usbssp";
				reg = <0x00 0x90f0000 0x00 0x4000>,
						<0x00 0x90f4000 0x00 0x4000>,
						<0x00 0x90f8000 0x00 0x8000>;
				reg-names = "otg", "dev", "xhci";
				interrupts = <GIC_SPI USB_C_SSP_2_HOST_IRQ IRQ_TYPE_LEVEL_HIGH>,	/* host irq */
						<GIC_SPI USB_C_SSP_2_PERIPHERAL_IRQ IRQ_TYPE_LEVEL_HIGH>,	/* peripheral irq */
						<GIC_SPI USB_C_SSP_2_OTG_IRQ IRQ_TYPE_LEVEL_HIGH>,	/* otgirq */
						<GIC_SPI USB_C_SSP_2_WAKEUP_IRQ IRQ_TYPE_LEVEL_HIGH>;	/* wakeup irq */
				interrupt-names = "host",
						"peripheral",
						"otg",
						"wakeup";
				maximum-speed = "super-speed-plus";
				dr_mode = "host";
				status = "disabled";
				phys = <&usb3_phy2>;
				phy-names = "cdnsp,usb3-phy";
			};
		};

		usb2_phy8:usb-phy@9100000 {
			compatible = "cix,sky1-usb2-phy";
			resets = <&src SKY1_USBPHY_HS8_PRST_N>;
			reset-names = "preset";
			#phy-cells = <0>;
			status = "disabled";
		};

		usbc_phy2:usb-phy@9110000 {
			#address-cells = <1>;
			#size-cells = <0>;
			compatible = "cix,sky1-usbdp-phy";
			reg = <0x00 0x9110000 0x00 0x40000>;
			status = "disabled";

			resets = <&src SKY1_USB_DP_PHY2_RST_N>,
					<&src SKY1_USB_DP_PHY2_PRST_N>;
			reset-names = "reset", "preset";

			clocks = <&scmi_clk CLK_TREE_USB3C_1_PHY3_GATE>;
			clock-names = "pclk";

			cix,usbphy_syscon = <&src>;

			usb3_phy2: usb-port {
				#phy-cells = <0>;
				reg = <0x0>;
				status = "disabled";
			};
			usbc2_dp_phy: dp-port {
				#phy-cells = <0>;
				reg = <0x1>;
				status = "disabled";
			};
		};

		sky1_usbss_3:usb@9150000 {
			compatible = "cix,sky1-usbssp";
			#address-cells = <2>;
			#size-cells = <2>;
			ranges;
			reg = <0x00 0x09150310 0x00 0x4>,
				<0x00 0x09150400 0x00 0x4>;
			reg-names = "axi_property", "controller_status";
			resets = <&src SKY1_USBC_SS5_PRST_N>,
				<&src SKY1_USBC_SS5_RST_N>;
			reset-names = "usb_preset", "usb_reset";
			clocks = <&scmi_clk CLK_TREE_USB3C_H2_CLK_SOF>,
				<&scmi_clk CLK_TREE_USB3C_2_AXI_GATE>,
				<&scmi_clk CLK_TREE_USB3C_H2_CLK_LPM>,
				<&scmi_clk CLK_TREE_USB3C_2_APB_GATE>;
			clock-names = "sof_clk", "usb_aclk", "lpm_clk", "usb_pclk";
			cix,usb_syscon = <&src>;
			axi_bmax_value = <0x7>;
			status = "disabled";
			usbss_3: usb-controller@9160000 {
				compatible = "cdns,usbssp";
				reg = <0x00 0x9160000 0x00 0x4000>,
						<0x00 0x9164000 0x00 0x4000>,
						<0x00 0x9168000 0x00 0x8000>;
				reg-names = "otg", "dev", "xhci";
				interrupts = <GIC_SPI USB_C_SSP_3_HOST_IRQ IRQ_TYPE_LEVEL_HIGH>,	/* host irq */
						<GIC_SPI USB_C_SSP_3_PERIPHERAL_IRQ IRQ_TYPE_LEVEL_HIGH>,	/* peripheral irq */
						<GIC_SPI USB_C_SSP_3_OTG_IRQ IRQ_TYPE_LEVEL_HIGH>,	/* otgirq */
						<GIC_SPI USB_C_SSP_3_WAKEUP_IRQ IRQ_TYPE_LEVEL_HIGH>;	/* wakeup irq */
				interrupt-names = "host",
						"peripheral",
						"otg",
						"wakeup";
				maximum-speed = "super-speed-plus";
				dr_mode = "host";
				status = "disabled";
				phys = <&usb3_phy3>;
				phy-names = "cdnsp,usb3-phy";
			};
		};

		usb2_phy9:usb-phy@9170000 {
			compatible = "cix,sky1-usb2-phy";
			resets = <&src SKY1_USBPHY_HS9_PRST_N>;
			reset-names = "preset";
			#phy-cells = <0>;
			status = "disabled";
		};

		usbc_phy3:usb-phy@9180000 {
			#address-cells = <1>;
			#size-cells = <0>;
			compatible = "cix,sky1-usbdp-phy";
			reg = <0x00 0x9180000 0x00 0x40000>;
			status = "disabled";

			resets = <&src SKY1_USB_DP_PHY3_RST_N>,
					<&src SKY1_USB_DP_PHY3_PRST_N>;
			reset-names = "reset", "preset";

			clocks = <&scmi_clk CLK_TREE_USB3C_2_PHY3_GATE>;
			clock-names = "pclk";

			cix,usbphy_syscon = <&src>;

			usb3_phy3: usb-port {
				#phy-cells = <0>;
				reg = <0x0>;
				status = "disabled";
			};
			usbc3_dp_phy: dp-port {
				#phy-cells = <0>;
				reg = <0x1>;
				status = "disabled";
			};
		};

		sky1_usbss_4:usb@91c0300 {
			compatible = "cix,sky1-usbssp";
			#address-cells = <2>;
			#size-cells = <2>;
			ranges;
			reg = <0x00 0x091c0314 0x00 0x4>,
				<0x00 0x091c0400 0x00 0x4>;
			reg-names = "axi_property", "controller_status";
			resets = <&src SKY1_USBC_SS2_PRST_N>,
				<&src SKY1_USBC_SS2_RST_N>;
			reset-names = "usb_preset", "usb_reset";
			clocks = <&scmi_clk CLK_TREE_USB3A_H0_CLK_SOF>,
				<&scmi_clk CLK_TREE_USB3A_0_AXI_GATE>,
				<&scmi_clk CLK_TREE_USB3A_H0_CLK_LPM>,
				<&scmi_clk CLK_TREE_USB3A_0_APB_GATE>;
			clock-names = "sof_clk", "usb_aclk", "lpm_clk", "usb_pclk";
			cix,usb_syscon = <&src>;
			axi_bmax_value = <0x7>;
			status = "disabled";
			usbss_4: usb-controller@91d0000 {
				compatible = "cdns,usbssp";
				reg = <0x00 0x91d0000 0x00 0x4000>,
						<0x00 0x91d4000 0x00 0x4000>,
						<0x00 0x91d8000 0x00 0x8000>;
				reg-names = "otg", "dev", "xhci";
				interrupts = <GIC_SPI USB_SSP_0_HOST_IRQ IRQ_TYPE_LEVEL_HIGH>,	/* host irq */
						<GIC_SPI USB_SSP_0_PERIPHERAL_IRQ IRQ_TYPE_LEVEL_HIGH>,	/* peripheral irq */
						<GIC_SPI USB_SSP_0_OTG_IRQ IRQ_TYPE_LEVEL_HIGH>,	/* otgirq */
						<GIC_SPI USB_SSP_0_WAKEUP_IRQ IRQ_TYPE_LEVEL_HIGH>;	/* wakeup irq */
				interrupt-names = "host",
						"peripheral",
						"otg",
						"wakeup";
				maximum-speed = "super-speed-plus";
				dr_mode = "otg";
				phys = <&usb3_phy4_0>;
				phy-names = "cdnsp,usb3-phy";
				status = "disabled";
			};
		};

		sky1_usbss_5:usb@91c0304 {
			compatible = "cix,sky1-usbssp";
			#address-cells = <2>;
			#size-cells = <2>;
			ranges;
			reg = <0x00 0x091c0324 0x00 0x4>,
				<0x00 0x091c0410 0x00 0x4>;
			reg-names = "axi_property", "controller_status";
			resets = <&src SKY1_USBC_SS3_PRST_N>,
				<&src SKY1_USBC_SS3_RST_N>;
			reset-names = "usb_preset", "usb_reset";
			clocks = <&scmi_clk CLK_TREE_USB3A_H1_CLK_SOF>,
				<&scmi_clk CLK_TREE_USB3A_1_AXI_GATE>,
				<&scmi_clk CLK_TREE_USB3A_H1_CLK_LPM>,
				<&scmi_clk CLK_TREE_USB3A_1_APB_GATE>;
			clock-names = "sof_clk", "usb_aclk", "lpm_clk", "usb_pclk";
			cix,usb_syscon = <&src>;
			axi_bmax_value = <0x7>;
			status = "disabled";
			usbss_5: usb-controller@91e0000 {
				compatible = "cdns,usbssp";
				reg = <0x00 0x91e0000 0x00 0x4000>,
						<0x00 0x91e4000 0x00 0x4000>,
						<0x00 0x91e8000 0x00 0x8000>;
				reg-names = "otg", "dev", "xhci";
				interrupts = <GIC_SPI USB_SSP_1_HOST_IRQ IRQ_TYPE_LEVEL_HIGH>,	/* host irq */
						<GIC_SPI USB_SSP_1_PERIPHERAL_IRQ IRQ_TYPE_LEVEL_HIGH>,	/* peripheral irq */
						<GIC_SPI USB_SSP_1_OTG_IRQ IRQ_TYPE_LEVEL_HIGH>,	/* otgirq */
						<GIC_SPI USB_SSP_1_WAKEUP_IRQ IRQ_TYPE_LEVEL_HIGH>;	/* wakeup irq */
				interrupt-names = "host",
						"peripheral",
						"otg",
						"wakeup";
				maximum-speed = "super-speed-plus";
				dr_mode = "otg";
				phys = <&usb3_phy4_1>;
				phy-names = "cdnsp,usb3-phy";
				status = "disabled";
			};
		};

		usb2_phy6:usb-phy@91f0000 {
			compatible = "cix,sky1-usb2-phy";
			resets = <&src SKY1_USBPHY_HS6_PRST_N>;
			reset-names = "preset";
			#phy-cells = <0>;
			status = "disabled";
		};

		usb2_phy7:usb-phy@9200000 {
			compatible = "cix,sky1-usb2-phy";
			resets = <&src SKY1_USBPHY_HS7_PRST_N>;
			reset-names = "preset";
			#phy-cells = <0>;
			status = "disabled";
		};

		usb3_phy4:usb-phy@9210000 {
			#address-cells = <1>;
			#size-cells = <0>;
			compatible = "cix,sky1-usb3-phy";
			reg = <0x00 0x09210000 0x00 0x40000>;
			status = "disabled";

			resets = <&src SKY1_USBPHY_SS_RST_N>,
					<&src SKY1_USBPHY_SS_PST_N>;
			reset-names = "reset", "preset";

			clocks = <&scmi_clk CLK_TREE_USB3A_PHY3_GATE>,
					<&scmi_clk CLK_TREE_USB3A_PHY_x2_REF>;
			clock-names = "apb_clk", "ref_clk";

			cix,usbphy_syscon = <&src>;

			usb3_phy4_0: usb-port@0 {
				#phy-cells = <0>;
				id = <0>;
				status = "disabled";
			};
			usb3_phy4_1: usb-port@1 {
				#phy-cells = <0>;
				id = <1>;
				status = "disabled";
			};
		};

		sky1_usbhs_0:usb@9250000 {
			compatible = "cix,sky1-usbssp";
			#address-cells = <2>;
			#size-cells = <2>;
			ranges;
			reg = <0x00 0x09250310 0x00 0x4>,
				<0x00 0x09250400 0x00 0x4>;
			reg-names = "axi_property", "controller_status";
			resets = <&src SKY1_USBC_HS0_PRST_N>,
				<&src SKY1_USBC_HS0_RST_N>;
			reset-names = "usb_preset", "usb_reset";
			clocks = <&scmi_clk CLK_TREE_USB2_0_CLK_SOF>,
				<&scmi_clk CLK_TREE_USB2_0_AXI_GATE>,
				<&scmi_clk CLK_TREE_USB2_0_CLK_LPM>,
				<&scmi_clk CLK_TREE_USB2_0_APB_GATE>;
			clock-names = "sof_clk", "usb_aclk", "lpm_clk", "usb_pclk";
			cix,usb_syscon = <&src>;
			axi_bmax_value = <0x7>;
			status = "disabled";
			usbhs_0: usb-controller@9260000 {
				compatible = "cdns,usbssp";
				reg = <0x00 0x9260000 0x00 0x4000>,
						<0x00 0x9264000 0x00 0x4000>,
						<0x00 0x9268000 0x00 0x8000>;
				reg-names = "otg", "dev", "xhci";
				interrupts = <GIC_SPI USB2_0_HOST_IRQ IRQ_TYPE_LEVEL_HIGH>,	/* host irq */
						<GIC_SPI USB2_0_PERIPHERAL_IRQ IRQ_TYPE_LEVEL_HIGH>,	/* peripheral irq */
						<GIC_SPI USB2_0_OTG_IRQ IRQ_TYPE_LEVEL_HIGH>,		/* otgirq */
						<GIC_SPI USB2_0_WAKEUP_IRQ IRQ_TYPE_LEVEL_HIGH>;	/* wakeup irq */
				interrupt-names = "host",
						"peripheral",
						"otg",
						"wakeup";
				maximum-speed = "high-speed";
				dr_mode = "host";
				status = "disabled";
			};
		};

		sky1_usbhs_1:usb@9280000 {
			compatible = "cix,sky1-usbssp";
			#address-cells = <2>;
			#size-cells = <2>;
			ranges;
			reg = <0x00 0x09280310 0x00 0x4>,
				<0x00 0x09280400 0x00 0x4>;
			reg-names = "axi_property", "controller_status";
			resets = <&src SKY1_USBC_HS1_PRST_N>,
				<&src SKY1_USBC_HS1_RST_N>;
			reset-names = "usb_preset", "usb_reset";
			clocks = <&scmi_clk CLK_TREE_USB2_1_CLK_SOF>,
				<&scmi_clk CLK_TREE_USB2_1_AXI_GATE>,
				<&scmi_clk CLK_TREE_USB2_1_CLK_LPM>,
				<&scmi_clk CLK_TREE_USB2_1_APB_GATE>;
			clock-names = "sof_clk", "usb_aclk", "lpm_clk", "usb_pclk";
			cix,usb_syscon = <&src>;
			axi_bmax_value = <0x7>;
			status = "disabled";
			usbhs_1: usb-controller@9290000 {
				compatible = "cdns,usbssp";
				reg = <0x00 0x9290000 0x00 0x4000>,
						<0x00 0x9294000 0x00 0x4000>,
						<0x00 0x9298000 0x00 0x8000>;
				reg-names = "otg", "dev", "xhci";
				interrupts = <GIC_SPI USB2_1_HOST_IRQ IRQ_TYPE_LEVEL_HIGH>,	/* host irq */
						<GIC_SPI USB2_1_PERIPHERAL_IRQ IRQ_TYPE_LEVEL_HIGH>,	/* peripheral irq */
						<GIC_SPI USB2_1_OTG_IRQ IRQ_TYPE_LEVEL_HIGH>,		/* otgirq */
						<GIC_SPI USB2_1_WAKEUP_IRQ IRQ_TYPE_LEVEL_HIGH>;	/* wakeup irq */
				interrupt-names = "host",
						"peripheral",
						"otg",
						"wakeup";
				maximum-speed = "high-speed";
				dr_mode = "host";
				status = "disabled";
			};
		};

		usb2_phy0:usb-phy@9270000 {
			compatible = "cix,sky1-usb2-phy";
			#phy-cells = <0>;
			resets = <&src SKY1_USBPHY_HS0_PRST_N>;
			reset-names = "preset";
			status = "disabled";
		};

		usb2_phy1:usb-phy@92a0000 {
			compatible = "cix,sky1-usb2-phy";
			#phy-cells = <0>;
			resets = <&src SKY1_USBPHY_HS1_PRST_N>;
			reset-names = "preset";
			status = "disabled";
		};

		sky1_usbhs_2:usb@92b0000 {
			compatible = "cix,sky1-usbssp";
			#address-cells = <2>;
			#size-cells = <2>;
			ranges;
			reg = <0x00 0x092b0310 0x00 0x4>,
				<0x00 0x092b0400 0x00 0x4>;
			reg-names = "axi_property", "controller_status";
			resets = <&src SKY1_USBC_HS2_PRST_N>,
				<&src SKY1_USBC_HS2_RST_N>;
			reset-names = "usb_preset", "usb_reset";
			clocks = <&scmi_clk CLK_TREE_USB2_2_CLK_SOF>,
				<&scmi_clk CLK_TREE_USB2_2_AXI_GATE>,
				<&scmi_clk CLK_TREE_USB2_2_CLK_LPM>,
				<&scmi_clk CLK_TREE_USB2_2_APB_GATE>;
			clock-names = "sof_clk", "usb_aclk", "lpm_clk", "usb_pclk";
			cix,usb_syscon = <&src>;
			axi_bmax_value = <0x7>;
			status = "disabled";
			usbhs_2: usb-controller@92c0000 {
				compatible = "cdns,usbssp";
				reg = <0x00 0x92c0000 0x00 0x4000>,
						<0x00 0x92c4000 0x00 0x4000>,
						<0x00 0x92c8000 0x00 0x8000>;
				reg-names = "otg", "dev", "xhci";
				interrupts = <GIC_SPI USB2_2_HOST_IRQ IRQ_TYPE_LEVEL_HIGH>,	/* host irq */
						<GIC_SPI USB2_2_PERIPHERAL_IRQ IRQ_TYPE_LEVEL_HIGH>,	/* peripheral irq */
						<GIC_SPI USB2_2_OTG_IRQ IRQ_TYPE_LEVEL_HIGH>,		/* otgirq */
						<GIC_SPI USB2_2_WAKEUP_IRQ IRQ_TYPE_LEVEL_HIGH>;	/* wakeup irq */
				interrupt-names = "host",
						"peripheral",
						"otg",
						"wakeup";
				maximum-speed = "high-speed";
				dr_mode = "host";
				status = "disabled";
			};
		};

		usb2_phy2:usb-phy@92d0000 {
			compatible = "cix,sky1-usb2-phy";
			#phy-cells = <0>;
			resets = <&src SKY1_USBPHY_HS2_PRST_N>;
			reset-names = "preset";
			status = "disabled";
		};

		sky1_usbhs_3:usb@92e0000 {
			compatible = "cix,sky1-usbssp";
			#address-cells = <2>;
			#size-cells = <2>;
			ranges;
			reg = <0x00 0x092e0310 0x00 0x4>,
				<0x00 0x092e0400 0x00 0x4>;
			reg-names = "axi_property", "controller_status";
			resets = <&src SKY1_USBC_HS3_PRST_N>,
				<&src SKY1_USBC_HS3_RST_N>;
			reset-names = "usb_preset", "usb_reset";
			clocks = <&scmi_clk CLK_TREE_USB2_3_CLK_SOF>,
				<&scmi_clk CLK_TREE_USB2_3_AXI_GATE>,
				<&scmi_clk CLK_TREE_USB2_3_CLK_LPM>,
				<&scmi_clk CLK_TREE_USB2_3_APB_GATE>;
			clock-names = "sof_clk", "usb_aclk", "lpm_clk", "usb_pclk";
			cix,usb_syscon = <&src>;
			axi_bmax_value = <0x7>;
			status = "disabled";
			usbhs_3: usb-controller@92f0000 {
				compatible = "cdns,usbssp";
				reg = <0x00 0x92f0000 0x00 0x4000>,
						<0x00 0x92f4000 0x00 0x4000>,
						<0x00 0x92f8000 0x00 0x8000>;
				reg-names = "otg", "dev", "xhci";
				interrupts = <GIC_SPI USB2_3_HOST_IRQ IRQ_TYPE_LEVEL_HIGH>,	/* host irq */
						<GIC_SPI USB2_3_PERIPHERAL_IRQ IRQ_TYPE_LEVEL_HIGH>,	/* peripheral irq */
						<GIC_SPI USB2_3_OTG_IRQ IRQ_TYPE_LEVEL_HIGH>,		/* otgirq */
						<GIC_SPI USB2_3_WAKEUP_IRQ IRQ_TYPE_LEVEL_HIGH>;	/* wakeup irq */
				interrupt-names = "host",
						"peripheral",
						"otg",
						"wakeup";
				maximum-speed = "high-speed";
				dr_mode = "host";
				status = "disabled";
			};
		};

		usb2_phy3:usb-phy@9300000 {
			compatible = "cix,sky1-usb2-phy";
			#phy-cells = <0>;
			resets = <&src SKY1_USBPHY_HS3_PRST_N>;
			reset-names = "preset";
			status = "disabled";
		};

		pcie_x8_rc: pcie@0a010000 { /* X8 */
			compatible = "cix,sky1-pcie-host";
			reg-names = "reg", "rcsu", "cfg", "msg";
			reg = <0x00 0x0a010000 0x00 0x10000>,
				  <0x00 0x0a000000 0x00 0x10000>,
				  <0x00 0x2c000000 0x00 0x4000000>,
				  <0x00 0x60000000 0x00 0x00100000>;
			device_type = "pci";
			vendor-id = <0x1f6c>;
			device-id = <0x0001>;
			#address-cells = <3>;
			#size-cells = <2>;
			bus-range = <0xc0 0xff>;
			max-link-speed = <4>;
			num-lanes = <8>;
			max-payload = <512>;
			ranges = <0x01000000 0x0 0x60100000 0x0 0x60100000 0x0 0x00100000>,
				 <0x02000000 0x0 0x60200000 0x0 0x60200000 0x0 0x1fe00000>,
				 <0x43000000 0x18 0x00000000 0x18 0x00000000 0x04 0x00000000>;
			cdns,no-inbound-bar;
			clocks = <&scmi_clk CLK_TREE_PCIE_CTRL0_CLK>,
			         <&scmi_clk CLK_TREE_PCIE_X8CTRL_APB>,
							 <&scmi_clk CLK_TREE_PCIE_REF_B0>;
			clock-names = "axi_clk", "apb_clk","refclk_b";
			power-domains = <&smc_devpd SKY1_PD_PCIE_CTRL0>;
			power-domain-names = "pcie_pd";
			resets = <&src SKY1_PCIE0_RESET_N>;
			reset-names = "pcie_reset";
			sky1,pcie-ctrl-id = <0x0>;
			msi-map = <0xc000 &its_pcie 0xc000 0x4000>;
			#interrupt-cells = <1>;
			interrupt-map-mask = <0 0 0 0x7>;
			interrupt-map = <0 0 0 1 &gic 0 0 GIC_SPI 407 IRQ_TYPE_LEVEL_HIGH>,
			                <0 0 0 2 &gic 0 0 GIC_SPI 408 IRQ_TYPE_LEVEL_HIGH>,
			                <0 0 0 3 &gic 0 0 GIC_SPI 409 IRQ_TYPE_LEVEL_HIGH>,
			                <0 0 0 4 &gic 0 0 GIC_SPI 410 IRQ_TYPE_LEVEL_HIGH>;
			interrupts = <GIC_SPI 402 IRQ_TYPE_EDGE_RISING>, /* AER (correctable) */
				     <GIC_SPI 403 IRQ_TYPE_EDGE_RISING>, /* AER (fatal) */
				     <GIC_SPI 404 IRQ_TYPE_EDGE_RISING>, /* AER (non fatal) */
				     <GIC_SPI 405 IRQ_TYPE_LEVEL_HIGH>, /* local (some error status) */
				     <GIC_SPI 406 IRQ_TYPE_LEVEL_HIGH>, /* phy_interrupt (link speed and width change) */
				     <GIC_SPI 411 IRQ_TYPE_LEVEL_HIGH>; /* phy_state_chg_sts (power status change) */
			interrupt-names = "aer_c", "aer_f", "aer_nf",
					  "local", "phy_int", "phy_sta";
			sky1,aer-uncor-panic;
			iommu-map = <0xc000 &smmu_pciehub 0xc000 0x3fff>;
			phys = <&pcie_x8_phy>;
			phy-names = "cdns,pcie-phy";
			status = "disabled";
		};

		pcie0_phy: pcie_phy@0a020000 {
			#address-cells = <1>;
			#size-cells = <0>;
			compatible = "cix,sky1-pcie-phy";
			reg = <0x00 0x0a020000 0x00 0x40000>;
			status = "disabled";
			clocks =<&scmi_clk CLK_TREE_PCIE_X8_PHY_APB>,
				<&scmi_clk CLK_TREE_PCIE_REF_PHY_X8>;

			clock-names = "pclk", "refclk";

			pcie_x8_phy: link@0 {
				#phy-cells = <0>;
				reg = <0x0>;
				num-lanes = <8>;
				status = "disabled";
			};
		};

		pcie_x4_rc: pcie@0a070000 { /* X4 */
			compatible = "cix,sky1-pcie-host";
			reg-names = "reg", "rcsu", "cfg", "msg";
			reg = <0x00 0x0a070000 0x00 0x10000>,
				  <0x00 0x0a060000 0x00 0x10000>,
				  <0x00 0x29000000 0x00 0x3000000>,
				  <0x00 0x50000000 0x00 0x00100000>;
			device_type = "pci";
			vendor-id = <0x1f6c>;
			device-id = <0x0001>;
			#address-cells = <3>;
			#size-cells = <2>;
			bus-range = <0x90 0xbf>;
			max-link-speed = <4>;
			num-lanes = <4>;
			max-payload = <512>;
			ranges = <0x01000000 0x00 0x50100000 0x00 0x50100000 0x00 0x00100000>,
				 <0x02000000 0x00 0x50200000 0x00 0x50200000 0x00 0x0fe00000>,
				 <0x43000000 0x14 0x00000000 0x14 0x00000000 0x04 0x00000000>;
			cdns,no-inbound-bar;
			clocks = <&scmi_clk CLK_TREE_PCIE_CTRL1_CLK>,
			         <&scmi_clk CLK_TREE_PCIE_X4CTRL_APB>,
				 <&scmi_clk CLK_TREE_PCIE_REF_B1>;
			clock-names = "axi_clk", "apb_clk", "refclk_b";
			resets = <&src SKY1_PCIE1_RESET_N>;
			reset-names = "pcie_reset";
			sky1,pcie-ctrl-id = <0x1>;
			msi-map = <0x9000 &its_pcie 0x9000 0x3000>;
			#interrupt-cells = <1>;
			interrupt-map-mask = <0 0 0 0x7>;
			interrupt-map = <0 0 0 1 &gic 0 0 GIC_SPI 417 IRQ_TYPE_LEVEL_HIGH>,
			                <0 0 0 2 &gic 0 0 GIC_SPI 418 IRQ_TYPE_LEVEL_HIGH>,
			                <0 0 0 3 &gic 0 0 GIC_SPI 419 IRQ_TYPE_LEVEL_HIGH>,
			                <0 0 0 4 &gic 0 0 GIC_SPI 420 IRQ_TYPE_LEVEL_HIGH>;
			interrupts = <GIC_SPI 412 IRQ_TYPE_EDGE_RISING>, /* AER (correctable) */
				     <GIC_SPI 413 IRQ_TYPE_EDGE_RISING>, /* AER (fatal) */
				     <GIC_SPI 414 IRQ_TYPE_EDGE_RISING>, /* AER (non fatal) */
				     <GIC_SPI 415 IRQ_TYPE_LEVEL_HIGH>, /* local (some error status) */
				     <GIC_SPI 416 IRQ_TYPE_LEVEL_HIGH>, /* phy_interrupt (link speed and width change) */
				     <GIC_SPI 421 IRQ_TYPE_LEVEL_HIGH>; /* phy_state_chg_sts (power status change) */
			interrupt-names = "aer_c", "aer_f", "aer_nf",
					  "local", "phy_int", "phy_sta";
			sky1,aer-uncor-panic;
			iommu-map = <0x9000 &smmu_pciehub 0x9000 0x2fff>;
			phys = <&pcie_x4_phy>;
			phy-names = "cdns,pcie-phy";
			status = "disabled";
		};

		pcie1_phy: pcie_phy@0a080000 {
			#address-cells = <1>;
			#size-cells = <0>;
			compatible = "cix,sky1-pcie-phy";
			reg = <0x00 0x0a080000 0x00 0x40000>;
			status = "disabled";
			clocks = <&scmi_clk CLK_TREE_PCIE_X4_PHY_APB>,
				<&scmi_clk CLK_TREE_PCIE_REF_PHY_X4>;

			clock-names = "pclk", "refclk";

			pcie_x4_phy: link@0 {
				#phy-cells = <0>;
				reg = <0x0>;
				num-lanes = <4>;
				status = "disabled";
			};
		};

		pcie_x2_rc: pcie@0a0c0000 { /* X2 */
			compatible = "cix,sky1-pcie-host";
			reg-names = "reg", "rcsu", "cfg", "msg";
			reg = <0x00 0x0a0c0000 0x00 0x10000>,
				  <0x00 0x0a060000 0x00 0x10000>,
				  <0x00 0x26000000 0x00 0x3000000>,
				  <0x00 0x40000000 0x00 0x00100000>;
			device_type = "pci";
			vendor-id = <0x1f6c>;
			device-id = <0x0001>;
			#address-cells = <3>;
			#size-cells = <2>;
			bus-range = <0x60 0x8f>;
			max-link-speed = <4>;
			num-lanes = <2>;
			max-payload = <512>;
			ranges = <0x01000000 0x0 0x40100000 0x0 0x40100000 0x0 0x00100000>,
				 <0x02000000 0x0 0x40200000 0x0 0x40200000 0x0 0x0fe00000>,
				 <0x43000000 0x10 0x00000000 0x10 0x00000000 0x04 0x00000000>;
			cdns,no-inbound-bar;
			clocks = <&scmi_clk CLK_TREE_PCIE_CTRL2_CLK>,
			         <&scmi_clk CLK_TREE_PCIE_X2CTRL_APB>,
				 <&scmi_clk CLK_TREE_PCIE_REF_B2>;
			clock-names = "axi_clk", "apb_clk", "refclk_b";

			resets = <&src SKY1_PCIE2_RESET_N>;
			reset-names = "pcie_reset";
			sky1,pcie-ctrl-id = <0x2>;
			msi-map = <0x6000 &its_pcie 0x6000 0x3000>;
			#interrupt-cells = <1>;
			interrupt-map-mask = <0 0 0 0x7>;
			interrupt-map = <0 0 0 1 &gic 0 0 GIC_SPI 427 IRQ_TYPE_LEVEL_HIGH>,
			                <0 0 0 2 &gic 0 0 GIC_SPI 428 IRQ_TYPE_LEVEL_HIGH>,
			                <0 0 0 3 &gic 0 0 GIC_SPI 429 IRQ_TYPE_LEVEL_HIGH>,
			                <0 0 0 4 &gic 0 0 GIC_SPI 430 IRQ_TYPE_LEVEL_HIGH>;
			interrupts = <GIC_SPI 422 IRQ_TYPE_EDGE_RISING>, /* AER (correctable) */
				     <GIC_SPI 423 IRQ_TYPE_EDGE_RISING>, /* AER (fatal) */
				     <GIC_SPI 424 IRQ_TYPE_EDGE_RISING>, /* AER (non fatal) */
				     <GIC_SPI 425 IRQ_TYPE_LEVEL_HIGH>, /* local (some error status) */
				     <GIC_SPI 426 IRQ_TYPE_LEVEL_HIGH>, /* phy_interrupt (link speed and width change) */
				     <GIC_SPI 451 IRQ_TYPE_LEVEL_HIGH>; /* phy_state_chg_sts (power status change) */
			interrupt-names = "aer_c", "aer_f", "aer_nf",
					  "local", "phy_int", "phy_sta";
			sky1,aer-uncor-panic;
			iommu-map = <0x6000 &smmu_pciehub 0x6000 0x2fff>;
			phys = <&pcie_x2_phy>;
			phy-names = "cdns,pcie-phy";
			status = "disabled";
		};

		pciex211_phy: pcie_phy@0a0f0000 {
			#address-cells = <1>;
			#size-cells = <0>;
			compatible = "cix,sky1-pcie-phy";
			reg = <0x00 0x0a0f0000 0x00 0x40000>;
			status = "disabled";
			clocks = <&scmi_clk CLK_TREE_PCIE_X211_PHY_APB>,
				<&scmi_clk CLK_TREE_PCIE_REF_PHY_X211>;

			clock-names = "pclk", "refclk";

			pcie_x1_phy0: link@0 {
				#phy-cells = <0>;
				reg = <0x0>;
				num-lanes = <1>;
				status = "disabled";
			};

			pcie_x1_phy1: link@1 {
				#phy-cells = <0>;
				reg = <0x1>;
				num-lanes = <1>;
				status = "disabled";
			};

			pcie_x2_phy: link@2 {
				#phy-cells = <0>;
				reg = <0x2>;
				num-lanes = <2>;
				status = "disabled";
			};
		};

		pcie_x1_1_rc: pcie@0a0e0000 { /* X1_1 */
			compatible = "cix,sky1-pcie-host";
			reg-names = "reg", "rcsu", "cfg", "msg";
			reg = <0x00 0x0a0e0000 0x00 0x10000>,
				  <0x00 0x0a060000 0x00 0x10000>,
				  <0x00 0x23000000 0x00 0x3000000>,
				  <0x00 0x38000000 0x00 0x00100000>;
			device_type = "pci";
			vendor-id = <0x1f6c>;
			device-id = <0x0001>;
			#address-cells = <3>;
			#size-cells = <2>;
			bus-range = <0x30 0x5f>;
			max-link-speed = <4>;
			num-lanes = <1>;
			max-payload = <512>;
			ranges = <0x01000000 0x0 0x38100000 0x0 0x38100000 0x0 0x00100000>,
				 <0x02000000 0x0 0x38200000 0x0 0x38200000 0x0 0x07e00000>,
				 <0x43000000 0x0C 0x00000000 0x0C 0x00000000 0x04 0x00000000>;
			cdns,no-inbound-bar;
			clocks = <&scmi_clk CLK_TREE_PCIE_CTRL4_CLK>,
			         <&scmi_clk CLK_TREE_PCIE_X1_1CTRL_APB>,
				 <&scmi_clk CLK_TREE_PCIE_REF_B4>;
			clock-names = "axi_clk", "apb_clk", "refclk_b";
			resets = <&src SKY1_PCIE4_RESET_N>;
			reset-names = "pcie_reset";
			sky1,pcie-ctrl-id = <0x3>;
			msi-map = <0x3000 &its_pcie 0x3000 0x3000>;
			#interrupt-cells = <1>;
			interrupt-map-mask = <0 0 0 0x7>;
			interrupt-map = <0 0 0 1 &gic 0 0 GIC_SPI 445 IRQ_TYPE_LEVEL_HIGH>,
			                <0 0 0 2 &gic 0 0 GIC_SPI 446 IRQ_TYPE_LEVEL_HIGH>,
			                <0 0 0 3 &gic 0 0 GIC_SPI 447 IRQ_TYPE_LEVEL_HIGH>,
			                <0 0 0 4 &gic 0 0 GIC_SPI 448 IRQ_TYPE_LEVEL_HIGH>;
			interrupts = <GIC_SPI 440 IRQ_TYPE_EDGE_RISING>, /* AER (correctable) */
				     <GIC_SPI 441 IRQ_TYPE_EDGE_RISING>, /* AER (fatal) */
				     <GIC_SPI 442 IRQ_TYPE_EDGE_RISING>, /* AER (non fatal) */
				     <GIC_SPI 443 IRQ_TYPE_LEVEL_HIGH>, /* local (some error status) */
				     <GIC_SPI 444 IRQ_TYPE_LEVEL_HIGH>, /* phy_interrupt (link speed and width change) */
				     <GIC_SPI 450 IRQ_TYPE_LEVEL_HIGH>; /* phy_state_chg_sts (power status change) */
			interrupt-names = "aer_c", "aer_f", "aer_nf",
					  "local", "phy_int", "phy_sta";
			sky1,aer-uncor-panic;
			iommu-map = <0x3000 &smmu_pciehub 0x3000 0x2fff>;
			phys = <&pcie_x1_phy1>;
			phy-names = "cdns,pcie-phy";
			status = "disabled";
		};

		pcie_x1_0_rc: pcie@0a0d0000 { /* X1_0 */
			compatible = "cix,sky1-pcie-host";
			reg-names = "reg", "rcsu", "cfg", "msg";
			reg = <0x00 0x0a0d0000 0x00 0x10000>,
				  <0x00 0x0a060000 0x00 0x10000>,
				  <0x00 0x20000000 0x00 0x3000000>,
				  <0x00 0x30000000 0x00 0x00100000>;
			device_type = "pci";
			vendor-id = <0x1f6c>;
			device-id = <0x0001>;
			#address-cells = <3>;
			#size-cells = <2>;
			bus-range = <0x00 0x2f>;
			max-link-speed = <4>;
			num-lanes = <1>;
			max-payload = <512>;
			ranges = <0x01000000 0x0 0x30100000 0x0 0x30100000 0x0 0x00100000>,
				 <0x02000000 0x0 0x30200000 0x0 0x30200000 0x0 0x07e00000>,
				 <0x43000000 0x08 0x00000000 0x08 0x00000000 0x04 0x00000000>;
			cdns,no-inbound-bar;
			clocks = <&scmi_clk CLK_TREE_PCIE_CTRL3_CLK>,
			         <&scmi_clk CLK_TREE_PCIE_X1_0CTRL_APB>,
				 <&scmi_clk CLK_TREE_PCIE_REF_B3>;
			clock-names = "axi_clk", "apb_clk", "refclk_b";
			resets = <&src SKY1_PCIE3_RESET_N>;
			reset-names = "pcie_reset";
			sky1,pcie-ctrl-id = <0x4>;
			msi-map = <0x0000 &its_pcie 0x0000 0x3000>;
			#interrupt-cells = <1>;
			interrupt-map-mask = <0 0 0 0x7>;
			interrupt-map = <0 0 0 1 &gic 0 0 GIC_SPI 436 IRQ_TYPE_LEVEL_HIGH>,
			                <0 0 0 2 &gic 0 0 GIC_SPI 437 IRQ_TYPE_LEVEL_HIGH>,
			                <0 0 0 3 &gic 0 0 GIC_SPI 438 IRQ_TYPE_LEVEL_HIGH>,
			                <0 0 0 4 &gic 0 0 GIC_SPI 439 IRQ_TYPE_LEVEL_HIGH>;
			interrupts = <GIC_SPI 431 IRQ_TYPE_EDGE_RISING>, /* AER (correctable) */
				     <GIC_SPI 432 IRQ_TYPE_EDGE_RISING>, /* AER (fatal) */
				     <GIC_SPI 433 IRQ_TYPE_EDGE_RISING>, /* AER (non fatal) */
				     <GIC_SPI 434 IRQ_TYPE_LEVEL_HIGH>, /* local (some error status) */
				     <GIC_SPI 435 IRQ_TYPE_LEVEL_HIGH>, /* phy_interrupt (link speed and width change) */
				     <GIC_SPI 449 IRQ_TYPE_LEVEL_HIGH>; /* phy_state_chg_sts (power status change) */
			interrupt-names = "aer_c", "aer_f", "aer_nf",
					  "local", "phy_int", "phy_sta";
			sky1,aer-uncor-panic;
			iommu-map = <0x0000 &smmu_pciehub 0x0000 0x2fff>;
			phys = <&pcie_x1_phy0>;
			phy-names = "cdns,pcie-phy";
			status = "disabled";
		};

		gic: interrupt-controller@0e001000 {
			compatible = "arm,gic-700", "arm,gic-v3";
			#address-cells = <2>;
			#interrupt-cells = <3>;
			#size-cells = <2>;
			single-redist;
			ranges;
			interrupt-controller;
#ifndef CONFIG_ARCH_CIX_EMU_FPGA
			#redistributor-regions = <12>;
			reg = <0x0 0x0e010000 0 0x10000>,	/* GICD */
			      <0x0 0x0e090000 0 0x40000>,	/* GICR */
			      <0x0 0x0e0d0000 0 0x40000>,       /* GICR1 */
			      <0x0 0x0e110000 0 0x40000>,       /* GICR2 */
			      <0x0 0x0e150000 0 0x40000>,       /* GICR3 */
			      <0x0 0x0e190000 0 0x40000>,       /* GICR4 */
			      <0x0 0x0e1d0000 0 0x40000>,       /* GICR5 */
			      <0x0 0x0e210000 0 0x40000>,       /* GICR6 */
			      <0x0 0x0e250000 0 0x40000>,       /* GICR7 */
			      <0x0 0x0e290000 0 0x40000>,       /* GICR8 */
			      <0x0 0x0e2d0000 0 0x40000>,       /* GICR9 */
			      <0x0 0x0e310000 0 0x40000>,       /* GICR10 */
			      <0x0 0x0e350000 0 0x40000>;       /* GICR11 */
#else
			#redistributor-regions = <1>;
			reg = <0x0 0x0e010000 0 0x10000>,       /* GICD */
			      <0x0 0x0e090000 0 0x40000>;       /* GICR */
#endif
			interrupts = <GIC_PPI 9 IRQ_TYPE_LEVEL_LOW>;
			interrupt-parent = <&gic>;

			its_pcie: its@0e050000 {
				compatible = "arm,gic-v3-its";
				msi-controller;
				reg = <0x0 0x0e050000 0x0 0x30000>;
			};
		};

		dsu_pmu: dsu_pmu {
			compatible = "arm,dsu-pmu";
			interrupts = <GIC_SPI 2 IRQ_TYPE_LEVEL_HIGH>;
			cpus = <&CPU0>, <&CPU1>, <&CPU2>, <&CPU3>,
				<&CPU4>, <&CPU5>, <&CPU6>, <&CPU7>,
				<&CPU8>, <&CPU9>, <&CPU10>, <&CPU11>;
			status = "okay";
		};

		cmn_pmu: cmn_pmu@10010000 {
			compatible = "arm,ci-700";
			reg = <0x0 0x10010000 0x0 0x3FF0000>;
			interrupts = <GIC_SPI 51 IRQ_TYPE_LEVEL_HIGH>;
			status = "okay";
		};

		cix_display: cix-display {
			compatible = "cix,display";
			//reset-control = <0x4>;
			status = "disabled";
		};

		dpu0: disp-controller@14010000 {
			device-id = <0>;
			#address-cells = <1>;
			#size-cells = <0>;
			compatible = "armchina,linlon-d6";
			reg = <0x0 0x14010000 0x0 0x20000>;
			interrupts = <GIC_SPI 316 IRQ_TYPE_LEVEL_HIGH>;
			iommus = <&smmu_mmhub 0>, <&smmu_mmhub 1>,
				 <&smmu_mmhub 3>, <&smmu_mmhub 4>;
			power-domains = <&smc_devpd SKY1_PD_DPU0>;
			power-domain-names = "dpu_pd";
			clocks = <&scmi_clk CLK_TREE_DPU0_ACLK>;
			clock-names = "aclk";
			resets = <&src SKY1_DPU0_RCSU_RESET_N>,
					<&src SKY1_DPU_RESET0_N>;
			reset-names = "rcsu_reset", "ip_reset";
			memory-region = <&dpu_gop>;
			enabled_by_gop = <0>;
			status = "disabled";

			dpu0_pipe0: pipeline@0 {
				reg = <0>;
				clocks = <&scmi_clk CLK_TREE_DP0_PIXEL0>;
				clock-names = "pxclk";
			};

			dpu0_pipe1: pipeline@1 {
				reg = <1>;
				clocks = <&scmi_clk CLK_TREE_DP0_PIXEL1>;
				clock-names = "pxclk";
			};
		};

		dpu1: disp-controller@14080000 {
			device-id = <1>;
			#address-cells = <1>;
			#size-cells = <0>;
			compatible = "armchina,linlon-d6";
			reg = <0x0 0x14080000 0x0 0x20000>;
			interrupts = <GIC_SPI 318 IRQ_TYPE_LEVEL_HIGH>;
			iommus = <&smmu_mmhub 6>, <&smmu_mmhub 7>,
				 <&smmu_mmhub 9>, <&smmu_mmhub 10>;
			power-domains = <&smc_devpd SKY1_PD_DPU1>;
			power-domain-names = "dpu_pd";
			clocks = <&scmi_clk CLK_TREE_DPU1_ACLK>;
			clock-names = "aclk";
			resets = <&src SKY1_DPU1_RCSU_RESET_N>,
					<&src SKY1_DPU_RESET1_N>;
			reset-names = "rcsu_reset", "ip_reset";
			memory-region = <&dpu_gop>;
			enabled_by_gop = <0>;
			status = "disabled";

			dpu1_pipe0: pipeline@0 {
				reg = <0>;
				clocks = <&scmi_clk CLK_TREE_DP1_PIXEL0>;
				clock-names = "pxclk";
			};

			dpu1_pipe1: pipeline@1 {
				reg = <1>;
				clocks = <&scmi_clk CLK_TREE_DP1_PIXEL1>;
				clock-names = "pxclk";
			};
		};

		dpu2: disp-controller@140f0000 {
			device-id = <2>;
			#address-cells = <1>;
			#size-cells = <0>;
			compatible = "armchina,linlon-d6";
			reg = <0x0 0x140f0000 0x0 0x20000>;
			interrupts = <GIC_SPI 320 IRQ_TYPE_LEVEL_HIGH>;
			iommus = <&smmu_mmhub 12>, <&smmu_mmhub 13>,
				 <&smmu_mmhub 15>, <&smmu_mmhub 16>;
			power-domains = <&smc_devpd SKY1_PD_DPU2>;
			power-domain-names = "dpu_pd";
			clocks = <&scmi_clk CLK_TREE_DPU2_ACLK>;
			clock-names = "aclk";
			resets = <&src SKY1_DPU2_RCSU_RESET_N>,
					<&src SKY1_DPU_RESET2_N>;
			reset-names = "rcsu_reset", "ip_reset";
			memory-region = <&dpu_gop>;
			enabled_by_gop = <0>;
			status = "disabled";

			dpu2_pipe0: pipeline@0 {
				reg = <0>;
				clocks = <&scmi_clk CLK_TREE_DP2_PIXEL0>;
				clock-names = "pxclk";
			};

			dpu2_pipe1: pipeline@1 {
				reg = <1>;
				clocks = <&scmi_clk CLK_TREE_DP2_PIXEL1>;
				clock-names = "pxclk";
			};
		};

		dpu3: disp-controller@14160000 {
			device-id = <3>;
			#address-cells = <1>;
			#size-cells = <0>;
			compatible = "armchina,linlon-d6";
			reg = <0x0 0x14160000 0x0 0x20000>;
			interrupts = <GIC_SPI 322 IRQ_TYPE_LEVEL_HIGH>;
			iommus = <&smmu_mmhub 18>, <&smmu_mmhub 19>,
				 <&smmu_mmhub 21>, <&smmu_mmhub 22>;
			power-domains = <&smc_devpd SKY1_PD_DPU3>;
			power-domain-names = "dpu_pd";
			clocks = <&scmi_clk CLK_TREE_DPU3_ACLK>;
			clock-names = "aclk";
			resets = <&src SKY1_DPU3_RCSU_RESET_N>,
					<&src SKY1_DPU_RESET3_N>;
			reset-names = "rcsu_reset", "ip_reset";
			memory-region = <&dpu_gop>;
			enabled_by_gop = <0>;
			status = "disabled";

			dpu3_pipe0: pipeline@0 {
				reg = <0>;
				clocks = <&scmi_clk CLK_TREE_DP3_PIXEL0>;
				clock-names = "pxclk";
			};

			dpu3_pipe1: pipeline@1 {
				reg = <1>;
				clocks = <&scmi_clk CLK_TREE_DP3_PIXEL1>;
				clock-names = "pxclk";
			};
		};

		dpu4: disp-controller@141d0000 {
			device-id = <4>;
			#address-cells = <1>;
			#size-cells = <0>;
			compatible = "armchina,linlon-d6";
			reg = <0x0 0x141d0000 0x0 0x20000>;
			interrupts = <GIC_SPI 324 IRQ_TYPE_LEVEL_HIGH>;
			iommus = <&smmu_mmhub 24>, <&smmu_mmhub 25>,
				 <&smmu_mmhub 27>, <&smmu_mmhub 28>;
			power-domains = <&smc_devpd SKY1_PD_DPU4>;
			power-domain-names = "dpu_pd";
			clocks = <&scmi_clk CLK_TREE_DPU4_ACLK>;
			clock-names = "aclk";
			resets = <&src SKY1_DPU4_RCSU_RESET_N>,
					<&src SKY1_DPU_RESET4_N>;
			reset-names = "rcsu_reset", "ip_reset";
			memory-region = <&dpu_gop>;
			enabled_by_gop = <0>;
			status = "disabled";

			dpu4_pipe0: pipeline@0 {
				reg = <0>;
				clocks = <&scmi_clk CLK_TREE_DP4_PIXEL0>;
				clock-names = "pxclk";
			};

			dpu4_pipe1: pipeline@1 {
				reg = <1>;
				clocks = <&scmi_clk CLK_TREE_DP4_PIXEL1>;
				clock-names = "pxclk";
			};
		};

		aeu0: aeu@14030000 {
			compatible = "armchina,linlon-aeu";
			reg = <0x0 0x14030000 0x0 0x20000>;
			interrupts = <GIC_SPI 317 IRQ_TYPE_LEVEL_HIGH>;
			interrupt-names = "AEU";
			iommus = <&smmu_mmhub 2>;
			power-domains = <&smc_devpd SKY1_PD_DPU0>;
			power-domain-names = "dpu_pd";
			clocks = <&scmi_clk CLK_TREE_DPU0_ACLK>;
			clock-names = "aclk";
			status = "disabled";
		};

		aeu1: aeu@140a0000 {
			compatible = "armchina,linlon-aeu";
			reg = <0x0 0x140a0000 0x0 0x20000>;
			interrupts = <GIC_SPI 319 IRQ_TYPE_LEVEL_HIGH>;
			interrupt-names = "AEU";
			iommus = <&smmu_mmhub 8>;
			power-domains = <&smc_devpd SKY1_PD_DPU1>;
			power-domain-names = "dpu_pd";
			clocks = <&scmi_clk CLK_TREE_DPU1_ACLK>;
			clock-names = "aclk";
			status = "disabled";
		};

		aeu2: aeu@14110000 {
			compatible = "armchina,linlon-aeu";
			reg = <0x0 0x14110000 0x0 0x20000>;
			interrupts = <GIC_SPI 321 IRQ_TYPE_LEVEL_HIGH>;
			interrupt-names = "AEU";
			iommus = <&smmu_mmhub 14>;
			power-domains = <&smc_devpd SKY1_PD_DPU2>;
			power-domain-names = "dpu_pd";
			clocks = <&scmi_clk CLK_TREE_DPU2_ACLK>;
			clock-names = "aclk";
			status = "disabled";
		};

		aeu3: aeu@14180000 {
			compatible = "armchina,linlon-aeu";
			reg = <0x0 0x14180000 0x0 0x20000>;
			interrupts = <GIC_SPI 323 IRQ_TYPE_LEVEL_HIGH>;
			interrupt-names = "AEU";
			iommus = <&smmu_mmhub 20>;
			power-domains = <&smc_devpd SKY1_PD_DPU3>;
			power-domain-names = "dpu_pd";
			clocks = <&scmi_clk CLK_TREE_DPU3_ACLK>;
			clock-names = "aclk";
			status = "disabled";
		};

		aeu4: aeu@141f0000 {
			compatible = "armchina,linlon-aeu";
			reg = <0x0 0x141f0000 0x0 0x20000>;
			interrupts = <GIC_SPI 325 IRQ_TYPE_LEVEL_HIGH>;
			interrupt-names = "AEU";
			iommus = <&smmu_mmhub 26>;
			power-domains = <&smc_devpd SKY1_PD_DPU4>;
			power-domain-names = "dpu_pd";
			clocks = <&scmi_clk CLK_TREE_DPU4_ACLK>;
			clock-names = "aclk";
			status = "disabled";
		};

		dp0: dp@14060000 {
			#address-cells = <1>;
			#size-cells = <0>;
			#sound-dai-cells = <0>;
			compatible = "cix,sky1-dptx";
			reg = <0x0 0x14064000 0x0 0x4000>,
				<0x0 0x14068000 0x0 0x4000>,
				<0x0 0x1406ff00 0x0 0x0100>,
				<0x0 0x14050000 0x0 0x304>;
			reg-names = "dp", "dsc", "dp_phy", "dp_rcsu";
			interrupts = <GIC_SPI 332 IRQ_TYPE_LEVEL_HIGH>;

			clocks = <&scmi_clk CLK_TREE_DPC0_APBCLK>,
					<&scmi_clk CLK_TREE_DPC0_VIDCLK0>,
					<&scmi_clk CLK_TREE_DPC0_VIDCLK1>;
			clock-names = "apb_clk", "vid_clk0", "vid_clk1";
			resets = <&src SKY1_DP0_RCSU_RESET_N>,
					<&src SKY1_DP_RESET0_N>;
			reset-names = "dp_rcsu_reset", "dp_reset";

			phys = <&usbc0_dp_phy>;
			phy-names = "dp_phy";
			support_d3_cmd = "yes"; /*yes: support D3 cmd no: not support support D3 cmd*/

			enabled_by_gop = <0>;

			status = "disabled";
		};

		dp1: dp@140d0000 {
			#address-cells = <1>;
			#size-cells = <0>;
			#sound-dai-cells = <0>;
			compatible = "cix,sky1-dptx";
			reg = <0x0 0x140d4000 0x0 0x4000>,
				<0x0 0x140d8000 0x0 0x4000>,
				<0x0 0x140dff00 0x0 0x0100>,
				<0x0 0x140c0000 0x0 0x304>;
			reg-names = "dp", "dsc", "dp_phy", "dp_rcsu";
			interrupts = <GIC_SPI 333 IRQ_TYPE_LEVEL_HIGH>;

			clocks = <&scmi_clk CLK_TREE_DPC1_APBCLK>,
					<&scmi_clk CLK_TREE_DPC1_VIDCLK0>,
					<&scmi_clk CLK_TREE_DPC1_VIDCLK1>;
			clock-names = "apb_clk", "vid_clk0", "vid_clk1";
			resets = <&src SKY1_DP1_RCSU_RESET_N>,
					<&src SKY1_DP_RESET1_N>;
			reset-names = "dp_rcsu_reset", "dp_reset";

			phys = <&usbc1_dp_phy>;
			phy-names = "dp_phy";
			support_d3_cmd = "yes"; /*yes: support D3 cmd no: not support support D3 cmd*/

			enabled_by_gop = <0>;

			status = "disabled";
		};

		dp2: dp@14140000 {
			#address-cells = <1>;
			#size-cells = <0>;
			#sound-dai-cells = <0>;
			compatible = "cix,sky1-dptx";
			reg = <0x0 0x14144000 0x0 0x4000>,
				<0x0 0x14148000 0x0 0x4000>,
				<0x0 0x1414c000 0x0 0x4000>,
				<0x0 0x14130000 0x0 0x320>;
			reg-names = "dp", "dsc", "dp_phy", "dp_rcsu";
			interrupts = <GIC_SPI 334 IRQ_TYPE_LEVEL_HIGH>;

			clocks = <&scmi_clk CLK_TREE_DPC2_APBCLK>,
					<&scmi_clk CLK_TREE_DPC2_VIDCLK0>,
					<&scmi_clk CLK_TREE_DPC2_VIDCLK1>;
			clock-names = "apb_clk", "vid_clk0", "vid_clk1";
			resets = <&src SKY1_DP2_RCSU_RESET_N>,
					<&src SKY1_DP_RESET2_N>,
					<&src SKY1_DP_PHY_RST_N>;
			reset-names = "dp_rcsu_reset", "dp_reset", "phy_reset";
			enabled_by_gop = <0>;
			cfg_adapter_port = <2>;
			status = "disabled";
		};

		dp3: dp@141b0000 {
			#address-cells = <1>;
			#size-cells = <0>;
			#sound-dai-cells = <0>;
			compatible = "cix,sky1-dptx";
			reg = <0x0 0x141b4000 0x0 0x4000>,
				<0x0 0x141b8000 0x0 0x4000>,
				<0x0 0x141bff00 0x0 0x0100>,
				<0x0 0x141a0000 0x0 0x304>;
			reg-names = "dp", "dsc", "dp_phy", "dp_rcsu";
			interrupts = <GIC_SPI 335 IRQ_TYPE_LEVEL_HIGH>;

			clocks = <&scmi_clk CLK_TREE_DPC3_APBCLK>,
					<&scmi_clk CLK_TREE_DPC3_VIDCLK0>,
					<&scmi_clk CLK_TREE_DPC3_VIDCLK1>;
			clock-names = "apb_clk", "vid_clk0", "vid_clk1";
			resets = <&src SKY1_DP3_RCSU_RESET_N>,
					<&src SKY1_DP_RESET3_N>;
			reset-names = "dp_rcsu_reset", "dp_reset";

			phys = <&usbc2_dp_phy>;
			phy-names = "dp_phy";
			support_d3_cmd = "yes"; /*yes: support D3 cmd no: not support support D3 cmd*/

			enabled_by_gop = <0>;

			status = "disabled";
		};

		dp4: dp@14220000 {
			#address-cells = <1>;
			#size-cells = <0>;
			#sound-dai-cells = <0>;
			compatible = "cix,sky1-dptx";
			reg = <0x0 0x14224000 0x0 0x4000>,
				<0x0 0x14228000 0x0 0x4000>,
				<0x0 0x1422ff00 0x0 0x0100>,
				<0x0 0x14210000 0x0 0x304>;
			reg-names = "dp", "dsc", "dp_phy", "dp_rcsu";
			interrupts = <GIC_SPI 336 IRQ_TYPE_LEVEL_HIGH>;

			clocks = <&scmi_clk CLK_TREE_DPC4_APBCLK>,
					<&scmi_clk CLK_TREE_DPC4_VIDCLK0>,
					<&scmi_clk CLK_TREE_DPC4_VIDCLK1>;
			clock-names = "apb_clk", "vid_clk0", "vid_clk1";
			resets = <&src SKY1_DP4_RCSU_RESET_N>,
					<&src SKY1_DP_RESET4_N>;
			reset-names = "dp_rcsu_reset", "dp_reset";

			phys = <&usbc3_dp_phy>;
			phy-names = "dp_phy";
			support_d3_cmd = "yes"; /*yes: support D3 cmd no: not support support D3 cmd*/

			enabled_by_gop = <0>;

			status = "disabled";
		};

		vpu: vpu@14230000 {
			compatible = "armChina,linlon-v8";
			reg = <0x0 0x14230000 0x0 0x10000>,
				<0x0 0x14240000 0x0 0x10000>;
			reg-names = "vpu_rcsu", "vpu";
			interrupts = <GIC_SPI 326 IRQ_TYPE_LEVEL_HIGH>;
			power-domains = <&smc_devpd SKY1_PD_VPU_TOP>,
					<&smc_devpd SKY1_PD_VPU_CORE0>,
					<&smc_devpd SKY1_PD_VPU_CORE1>,
					<&smc_devpd SKY1_PD_VPU_CORE2>,
					<&smc_devpd SKY1_PD_VPU_CORE3>,
					<&scmi_dvfs VPU_DFS_DOMAIN_ID>;
			#power-domain-cells = <2>;
			power-domain-names = "vpu_top", "vpu_core0", "vpu_core1",
					"vpu_core2", "vpu_core3", "perf";
			clocks = <&scmi_clk CLK_TREE_VPU_APBCLK>;
			clock-names = "vpu_clk";
			resets = <&src SKY1_VPU_RESET_N>,
					 <&src SKY1_VPU_RCSU_RESET_N>;
			reset-names = "vpu_reset", "vpu_rcsu_reset";
			status = "disabled";
		};

		npu: aipu@14260000 {
			compatible = "armchina,zhouyi";
			core_mask = <3>;
			power-domains = <&smc_devpd SKY1_PD_NPU_CORE0>,
				<&smc_devpd SKY1_PD_NPU_CORE1>,
				<&smc_devpd SKY1_PD_NPU_CORE2>,
				<&scmi_dvfs NPU_DFS_DOMAIN_ID>;
			power-domain-names = "pd_core0", "pd_core1", "pd_core2", "perf";
			cluster-partition = <0 0>;   /* x2 only: cluster #0 -> partition #0 */
			reg = <0x0 0x14260000 0x0 0x10000>;
			iommus = <&smmu_mmhub 0x1e>;
			gm-policy = <1>;            /* x2 only: 1: shared by tasks of all QoS level */
			interrupts = <GIC_SPI 327 IRQ_TYPE_LEVEL_HIGH>;
			status = "disabled";
		};

		i7_isp: armcb_isp@14340000 {
			#address-cells = <2>;
			#size-cells = <2>;
			compatible = "armcb,sky1-isp";
			reg = <0x0 0x14340000 0x0 0x10000>,
					<0x0 0x14360000 0x0 0x50000>;
			status = "disabled";
		};

		i7_isp_fake1:isp_fake1{
			compatible = "armcb,isp_fake";
		};

		i7_isp_fake2:isp_fake2{
			compatible = "armcb,isp_fake";
		};

		i7_isp_fake3:isp_fake3{
			compatible = "armcb,isp_fake";
		};

		gpu_physical_memory_group_manager: physical-memory-group-manager {
			compatible = "arm,physical-memory-group-manager";
		};

		gpu_protected_memory_allocator: protected-memory-allocator {
			compatible = "arm,protected-memory-allocator";
			memory-region = <&mali_protected>;
		};

		gpu: gpu@15010000 {
			compatible = "arm,mali-valhall";
			reg = <0x0 0x15000000 0x0 0x10000>,
				<0x0 0x15010000 0x0 0x480000>;
			reg-names = "gpu_rcsu", "gpu";
			interrupts = <GIC_SPI 237 IRQ_TYPE_LEVEL_HIGH>,
					<GIC_SPI 238 IRQ_TYPE_LEVEL_HIGH>,
					<GIC_SPI 239 IRQ_TYPE_LEVEL_HIGH>;
			interrupt-names = "JOB", "MMU", "GPU";
			system-coherency = <0>;
			physical-memory-group-manager = <&gpu_physical_memory_group_manager>;
			protected-memory-allocator = <&gpu_protected_memory_allocator>;
			power-domains = <&smc_devpd SKY1_PD_GPU>, <&scmi_dvfs 0>;
			power-domain-names = "pd_gpu", "perf";
			clocks = <&scmi_clk CLK_TREE_GPU_CLK_CORE>, <&scmi_clk CLK_TREE_GPU_CLK_STACKS>,
					<&scmi_clk CLK_TREE_GPU_CLK_200M>, <&scmi_clk CLK_TREE_GPU_CLK_400M>;
			clock-names = "gpu_clk_core", "gpu_clk_stacks",
						"gpu_clk_200M", "gpu_clk_400M";
			resets = <&src SKY1_GPU_RCSU_RESET_N>,
				 <&src SKY1_GPU_RESET_N>;
			reset-names = "gpu_rcsu_reset", "gpu_reset";
			gpu-microvolt = <820000>;
			#cooling-cells = <2>;  /* Requested by cooling device state */
			power_model@0 {
				/*Note: it was designed for the Juno platform, and may not be suitable for sky1.*/
				compatible = "arm,mali-simple-power-model";
				static-coefficient = <2427750>;
				dynamic-coefficient = <4687>;
				ts = <20000 2000 (-20) 2>;
				thermal-zone = "gpu-avg-thermal";
			};
			pbha {
				int_id_override = <2 0x23>, <4 0x23>, <16 0x22>, <17 0x32>,
						  <18 0x52>, <21 0x32>, <22 0x52>, <24 0x22>, <28 0x32>;
			};
		};

		hwclock: hwspinlock@06510000 {
			compatible = "sky1,hwspinlock";
			reg = <0x0 0x06510000 0x0 0x1000>;
			#hwlock-cells = <1>;
			status = "disabled";
		};

		gpt_timer0: gpt_timer@04110000 {
			compatible = "cix,sky1-gpt";
			reg = <0x0 0x04110000 0x0 0x2000>;
			interrupts = <GIC_SPI 467 IRQ_TYPE_LEVEL_HIGH>;
			clocks = <&scmi_clk CLK_TREE_FCH_TIMER_APB>,
						<&scmi_clk CLK_TREE_FCH_TIMER_FUN>;
			clock-names = "fch_timer_apb_clk", "fch_timer_func_clk";
			resets = <&src_fch SW_TIMER_RST_FUNC_N>;
			reset-names = "func_reset";
			status = "disabled";
		};

		gpt_timer1: gpt_timer@04112000 {
			compatible = "cix,sky1-gpt";
			reg = <0x0 0x04112000 0x0 0x2000>;
			interrupts = <GIC_SPI 468 IRQ_TYPE_LEVEL_HIGH>;
			clocks = <&scmi_clk CLK_TREE_FCH_TIMER_APB>,
						<&scmi_clk CLK_TREE_FCH_TIMER_FUN>;
			clock-names = "fch_timer_apb_clk", "fch_timer_func_clk";
			resets = <&src_fch SW_TIMER_RST_FUNC_N>;
			reset-names = "func_reset";
			status = "disabled";
		};

		gpt_timer2: gpt_timer@04114000 {
			compatible = "cix,sky1-gpt";
			reg = <0x0 0x04114000 0x0 0x2000>;
			interrupts = <GIC_SPI 469 IRQ_TYPE_LEVEL_HIGH>;
			clocks = <&scmi_clk CLK_TREE_FCH_TIMER_APB>,
						<&scmi_clk CLK_TREE_FCH_TIMER_FUN>;
			clock-names = "fch_timer_apb_clk", "fch_timer_func_clk";
			resets = <&src_fch SW_TIMER_RST_FUNC_N>;
			reset-names = "func_reset";
			status = "disabled";
		};

		gpt_timer3: gpt_timer@04116000 {
			compatible = "cix,sky1-gpt";
			reg = <0x0 0x04116000 0x0 0x2000>;
			interrupts = <GIC_SPI 470 IRQ_TYPE_LEVEL_HIGH>;
			clocks = <&scmi_clk CLK_TREE_FCH_TIMER_APB>,
						<&scmi_clk CLK_TREE_FCH_TIMER_FUN>;
			clock-names = "fch_timer_apb_clk", "fch_timer_func_clk";
			resets = <&src_fch SW_TIMER_RST_FUNC_N>;
			reset-names = "func_reset";
			status = "okay";
		};

		pwm0: pwm0@04110000 {
			compatible = "cix,sky1-pwm";
			reg = <0x0 0x04110000 0x0 0x1000>;
			clocks = <&scmi_clk CLK_TREE_FCH_TIMER_APB>,
						<&scmi_clk CLK_TREE_FCH_TIMER_FUN>;
			clock-names = "fch_pwm_apb_clk", "fch_pwm_func_clk";
			resets = <&src_fch SW_TIMER_RST_FUNC_N>;
			reset-names = "func_reset";
			#pwm-cells = <2>;
			status = "disabled";
		};

		pwm1: pwm1@04111000 {
			compatible = "cix,sky1-pwm";
			reg = <0x0 0x04111000 0x0 0x1000>;
			clocks = <&scmi_clk CLK_TREE_FCH_TIMER_APB>,
						<&scmi_clk CLK_TREE_FCH_TIMER_FUN>;
			clock-names = "fch_pwm_apb_clk", "fch_pwm_func_clk";
			resets = <&src_fch SW_TIMER_RST_FUNC_N>;
			reset-names = "func_reset";
			#pwm-cells = <2>;
			status = "disabled";
		};

		watchdog: watchdog@16003000 {
			compatible = "cix,sky1-wdt";
			reg = <0x0 0x16003000 0x0 0x1000
			       0x0 0x16008000 0x0 0x1000>;
			interrupts = <GIC_SPI 376 IRQ_TYPE_LEVEL_HIGH>;
			status = "disabled";
		};

		src: reset-controller@16000000 {
			compatible = "cix,sky1-src", "syscon";
			reg = <0x0 0x16000000 0x0 0x1000>;
			#reset-cells = <1>;
			status = "okay";
		};

		src_fch: reset-controller@04160000 {
			compatible = "cix,sky1-src-fch", "syscon";
			reg = <0x0 0x04160000 0x0 0x90>;
			#reset-cells = <1>;
			status = "okay";
		};

		s5_gpio0: gpio-controller@16004000 {
			compatible = "cdns,gpio-r1p02";
			reg = <0x0 0x16004000 0x0 0x1000>;
			clocks = <&s5_gpio_apb_clk>;

			interrupts = <GIC_SPI 372 IRQ_TYPE_LEVEL_HIGH>;

			gpio-controller;
			#gpio-cells = <2>;
			ngpios = <32>;

			interrupt-controller;
			#interrupt-cells = <2>;
			status = "disabled";
		};

		s5_gpio1: gpio-controller@16005000 {
			compatible = "cdns,gpio-r1p02";
			reg = <0x0 0x16005000 0x0 0x1000>;
			clocks = <&s5_gpio_apb_clk>;

			interrupts = <GIC_SPI 373 IRQ_TYPE_LEVEL_HIGH>;

			gpio-controller;
			#gpio-cells = <2>;
			ngpios = <10>;

			interrupt-controller;
			#interrupt-cells = <2>;
			status = "disabled";
		};

		s5_gpio2: gpio-controller@16006000 {
			compatible = "cdns,gpio-r1p02";
			reg = <0x0 0x16006000 0x0 0x1000>;
			clocks = <&s5_gpio_apb_clk>;

			interrupts = <GIC_SPI 374 IRQ_TYPE_LEVEL_HIGH>;

			gpio-controller;
			#gpio-cells = <2>;
			ngpios = <10>;

			interrupt-controller;
			#interrupt-cells = <2>;
			status = "disabled";
		};

		fch_gpio0: gpio-controller@4120000 {
			compatible = "cdns,gpio-r1p02";
			reg = <0x0 0x4120000 0x0 0x1000>;
			clocks = <&scmi_clk CLK_TREE_FCH_GPIO_APB>;
			clock-names = "fch_gpio_apb_clk";

			resets = <&src_fch SW_GPIO_RST_APB_N>;
			reset-names = "apb_reset";

			interrupts = <GIC_SPI 304 IRQ_TYPE_LEVEL_HIGH>;

			gpio-controller;
			#gpio-cells = <2>;
			ngpios = <32>;

			interrupt-controller;
			#interrupt-cells = <2>;
			status = "disabled";
		};

		fch_gpio1: gpio-controller@4130000 {
			compatible = "cdns,gpio-r1p02";
			reg = <0x0 0x4130000 0x0 0x1000>;
			clocks = <&scmi_clk CLK_TREE_FCH_GPIO_APB>;
			clock-names = "fch_gpio_apb_clk";

			resets = <&src_fch SW_GPIO_RST_APB_N>;
			reset-names = "apb_reset";

			interrupts = <GIC_SPI 305 IRQ_TYPE_LEVEL_HIGH>;

			gpio-controller;
			#gpio-cells = <2>;
			ngpios = <32>;

			interrupt-controller;
			#interrupt-cells = <2>;
			status = "disabled";
		};

		fch_gpio2: gpio-controller@4140000 {
			compatible = "cdns,gpio-r1p02";
			reg = <0x0 0x4140000 0x0 0x1000>;
			clocks = <&scmi_clk CLK_TREE_FCH_GPIO_APB>;
			clock-names = "fch_gpio_apb_clk";

			resets = <&src_fch SW_GPIO_RST_APB_N>;
			reset-names = "apb_reset";

			interrupts = <GIC_SPI 306 IRQ_TYPE_LEVEL_HIGH>;

			gpio-controller;
			#gpio-cells = <2>;
			ngpios = <32>;

			interrupt-controller;
			#interrupt-cells = <2>;
			status = "disabled";
		};

		fch_gpio3: gpio-controller@4150000 {
			compatible = "cdns,gpio-r1p02";
			reg = <0x0 0x4150000 0x0 0x1000>;
			clocks = <&scmi_clk CLK_TREE_FCH_GPIO_APB>;
			clock-names = "fch_gpio_apb_clk";

			resets = <&src_fch SW_GPIO_RST_APB_N>;
			reset-names = "apb_reset";

			interrupts = <GIC_SPI 307 IRQ_TYPE_LEVEL_HIGH>;

			gpio-controller;
			#gpio-cells = <2>;
			ngpios = <17>;

			interrupt-controller;
			#interrupt-cells = <2>;
			status = "disabled";
		};

		iomuxc_s5: pinctrl_s5_sky1 {
			compatible = "cix,sky1-iomuxc-s5";
			reg = <0x0 0x16007000 0x0 0x1000>;
		};

		iomuxc: pinctrl_sky1 {
			compatible = "cix,sky1-iomuxc";
			reg = <0x0 0x04170000 0x0 0x1000>;
		};

		nvmem: nvmem_fw {
			compatible = "cix,sky1-nvmem-fw";
			#address-cells = <1>;
			#size-cells = <1>;
			status = "okay";

			npu_harvest_0: npu_harveset_0@1 {
				reg = <0x1 0x1>;
				bits = <7 1>;
			};

			opn: opn@4c7 {
				reg = <0x4dc 0x8>;
				bits = <0 64>;
			};
		};

		sky1_top: sky1_top {
			compatible = "cix,sky1-top";
			reg = <0x0 0x83E01000 0x0 0x2000>;
			nvmem-cells = <&opn>;
			nvmem-cell-names = "opn";
			status = "okay";
		};

		cix_csi_rcsu_0: cix_csi_rcsu@14270000 {
			compatible = "cix,cix-csi-rcsu-hw";
			reg = <0x0 0x14270000 0x0 0x10000>;
			status = "disabled";
		};

		cix_csi_rcsu_1: cix_csi_rcsu@142D0000 {
			compatible = "cix,cix-csi-rcsu-hw";
			reg = <0x0 0x142D0000 0x0 0x10000>;
			status = "disabled";
		};

		cix_bridge_0: cix_bridge@142B0000 {
			compatible = "cix,cix-bridge";
			clocks = <&scmi_clk CLK_TREE_CSI_DMA0_PCLK>,
						<&scmi_clk CLK_TREE_ISP_SCLK>;
			clock-names = "dma_pclk", "dma_sclk";
			resets = <&src SKY1_CSIBRDGE0_RST_N>;
			reset-names = "csibridge_reset";
			reg = <0x0 0x142B0000 0x0 0x10000>;
			cix,hw = <&cix_csi_rcsu_0>;
			interrupts = <GIC_SPI 460 IRQ_TYPE_LEVEL_HIGH>;
			interface = <0 0>;
			axi-uid = <0x21>;
			iommus = <&smmu_mmhub 0x21>;
			status = "disabled";
		};

		cix_bridge_1: cix_bridge@142C0000 {
			compatible = "cix,cix-bridge";
			clocks = <&scmi_clk CLK_TREE_CSI_DMA1_PCLK>,
						<&scmi_clk CLK_TREE_ISP_SCLK>;
			clock-names = "dma_pclk", "dma_sclk";
			resets = <&src SKY1_CSIBRDGE1_RST_N>;
			reset-names = "csibridge_reset";
			reg = <0x0 0x142C0000 0x0 0x10000>;
			cix,hw = <&cix_csi_rcsu_0>;
			interrupts = <GIC_SPI 461 IRQ_TYPE_LEVEL_HIGH>;
			interface = <0 0>;
			axi-uid= <0x21>;
			status = "disabled";
		};

		cix_bridge_2: cix_bridge@14310000 {
			compatible = "cix,cix-bridge";
			clocks = <&scmi_clk CLK_TREE_CSI_DMA2_PCLK>,
						<&scmi_clk CLK_TREE_ISP_SCLK>;
			clock-names = "dma_pclk", "dma_sclk";
			resets = <&src SKY1_CSIBRDGE2_RST_N>;
			reset-names = "csibridge_reset";
			reg = <0x0 0x14310000 0x0 0x10000>;
			cix,hw = <&cix_csi_rcsu_1>;
			interrupts = <GIC_SPI 462 IRQ_TYPE_LEVEL_HIGH>;
			interface = <0 0>;
			axi-uid= <0x22>;
			iommus = <&smmu_mmhub 0x22>;
			status = "disabled";
		};

		cix_bridge_3: cix_bridge@14320000 {
			compatible = "cix,cix-bridge";
			clocks = <&scmi_clk CLK_TREE_CSI_DMA3_PCLK>,
						<&scmi_clk CLK_TREE_ISP_SCLK>;
			clock-names = "dma_pclk", "dma_sclk";
			resets = <&src SKY1_CSIBRDGE3_RST_N>;
			reset-names = "csibridge_reset";
			reg = <0x0 0x14320000 0x0 0x10000>;
			cix,hw = <&cix_csi_rcsu_1>;
			interrupts = <GIC_SPI 463 IRQ_TYPE_LEVEL_HIGH>;
			interface = <0 0>;
			axi-uid = <0x21>;
			status = "disabled";
		};

		cix_mipi_csi_0: csi@14280000 {
			compatible = "cix,cix-mipi-csi2";
			#address-cells = <2>;
			#size-cells = <2>;
			clocks = <&scmi_clk CLK_TREE_CSI_CTRL0_PCLK>,
						<&scmi_clk CLK_TREE_CSI_CTRL0_SYSCLK>,
						<&scmi_clk CLK_TREE_CSI_CTRL0_PIXEL0_CLK>,
						<&scmi_clk CLK_TREE_CSI_CTRL0_PIXEL1_CLK>,
						<&scmi_clk CLK_TREE_CSI_CTRL0_PIXEL2_CLK>,
						<&scmi_clk CLK_TREE_CSI_CTRL0_PIXEL3_CLK>;
			clock-names = "csi_pclk", "csi_sclk", "csi_p0clk",
							"csi_p1clk", "csi_p2clk", "csi_p3clk";
			resets = <&src SKY1_CSI_RCSU0_RESET_N>,
						<&src SKY1_CSI0_RST_N>;
			reset-names = "rcsu_reset", "csi_reset";
			reg = <0x0 0x14280000 0x0 0x10000>;
			interrupts = <GIC_SPI 452 IRQ_TYPE_LEVEL_HIGH>,
							<GIC_SPI 453 IRQ_TYPE_LEVEL_HIGH>;
			status = "disabled";
		};

		cix_mipi_csi_1: csi@14290000 {
			compatible = "cix,cix-mipi-csi2";
			#address-cells = <2>;
			#size-cells = <2>;
			clocks = <&scmi_clk CLK_TREE_CSI_CTRL1_PCLK>,
						<&scmi_clk CLK_TREE_CSI_CTRL1_SYSCLK>,
						<&scmi_clk CLK_TREE_CSI_CTRL1_PIXEL0_CLK>;
			clock-names = "csi_pclk", "csi_sclk", "csi_p0clk";
			resets = <&src SKY1_CSI1_RST_N>;
			reset-names = "csi_reset";
			reg = <0x0 0x14290000 0x0 0x10000>;
			interrupts = <GIC_SPI 454 IRQ_TYPE_LEVEL_HIGH>,
							<GIC_SPI 455 IRQ_TYPE_LEVEL_HIGH>;
			status = "disabled";
		};

		cix_mipi_csi_2: csi@142E0000 {
			compatible = "cix,cix-mipi-csi2";
			#address-cells = <2>;
			#size-cells = <2>;
			clocks = <&scmi_clk CLK_TREE_CSI_CTRL2_PCLK>,
						<&scmi_clk CLK_TREE_CSI_CTRL2_SYSCLK>,
						<&scmi_clk CLK_TREE_CSI_CTRL2_PIXEL0_CLK>,
						<&scmi_clk CLK_TREE_CSI_CTRL2_PIXEL1_CLK>,
						<&scmi_clk CLK_TREE_CSI_CTRL2_PIXEL2_CLK>,
						<&scmi_clk CLK_TREE_CSI_CTRL2_PIXEL3_CLK>;
			clock-names = "csi_pclk", "csi_sclk", "csi_p0clk",
							"csi_p1clk", "csi_p2clk", "csi_p3clk";
			resets = <&src SKY1_CSI_RCSU1_RESET_N>,
						<&src SKY1_CSI2_RST_N>;
			reset-names = "rcsu_reset", "csi_reset";
			reg = <0x0 0x142E0000 0x0 0x10000>;
			interrupts = <GIC_SPI 456 IRQ_TYPE_LEVEL_HIGH>,
							<GIC_SPI 457 IRQ_TYPE_LEVEL_HIGH>;
			status = "disabled";
		};

		cix_mipi_csi_3: csi@142F0000 {
			compatible = "cix,cix-mipi-csi2";
			#address-cells = <2>;
			#size-cells = <2>;
			clocks = <&scmi_clk CLK_TREE_CSI_CTRL3_PCLK>,
						<&scmi_clk CLK_TREE_CSI_CTRL3_SYSCLK>,
						<&scmi_clk CLK_TREE_CSI_CTRL3_PIXEL0_CLK>;
			clock-names = "csi_pclk", "csi_sclk", "csi_p0clk";
			resets = <&src SKY1_CSI3_RST_N>;
			reset-names = "csi_reset";
			reg = <0x0 0x142F0000 0x0 0x10000>;
			interrupts = <GIC_SPI 458 IRQ_TYPE_LEVEL_HIGH>,
							<GIC_SPI 459 IRQ_TYPE_LEVEL_HIGH>;
			status = "disabled";
		};

		cix_dphy_0: cix_dph_0 {
			compatible = "cix,cix-mipi-dphy-rx";
			cix,hw = <&cix_dphy_hw_0>;
			status = "disabled";
		};

		cix_dphy_1: cix_dph_1 {
			compatible = "cix,cix-mipi-dphy-rx";
			cix,hw = <&cix_dphy_hw_0>;
			status = "disabled";
		};

		cix_dphy_2: cix_dph_2 {
			compatible = "cix,cix-mipi-dphy-rx";
			cix,hw = <&cix_dphy_hw_0>;
			status = "disabled";
		};

		cix_dphy_3: cix_dph_3 {
			compatible = "cix,cix-mipi-dphy-rx";
			cix,hw = <&cix_dphy_hw_1>;
			status = "disabled";
		};

		cix_dphy_4: cix_dph_4 {
			compatible = "cix,cix-mipi-dphy-rx";
			cix,hw = <&cix_dphy_hw_1>;
			status = "disabled";
		};

		cix_dphy_5: cix_dph_5 {
			compatible = "cix,cix-mipi-dphy-rx";
			cix,hw = <&cix_dphy_hw_1>;
			status = "disabled";
		};

		cix_dphy_hw_0: phy@142A0000 {
			compatible = "cix,cix-mipi-dphy-hw";
			#address-cells = <2>;
			#size-cells = <2>;
			clocks = <&scmi_clk CLK_TREE_CSI_PHY0_PSM>,
						<&scmi_clk CLK_TREE_CSI_PHY0_APBCLK>;
			clock-names = "phy_psmclk", "phy_apbclk";
			resets = <&src SKY1_CSIDPHY_PRST0_N>,
						<&src SKY1_CSIDPHY_CMNRST0_N>;
			reset-names = "phy_prst", "phy_cmnrst";
			reg = <0x0 0x142A0000 0x0 0x10000>;
			status = "disabled";
		};

		cix_dphy_hw_1: phy@14300000 {
			compatible = "cix,cix-mipi-dphy-hw";
			#address-cells = <2>;
			#size-cells = <2>;
			clocks = <&scmi_clk CLK_TREE_CSI_PHY1_PSM>,
						<&scmi_clk CLK_TREE_CSI_PHY1_APBCLK>;
			clock-names = "phy_psmclk", "phy_apbclk";
			resets = <&src SKY1_CSIDPHY_PRST1_N>,
						<&src SKY1_CSIDPHY_CMNRST1_N>;
			reset-names = "phy_prst", "phy_cmnrst";
			reg = <0x0 0x14300000 0x0 0x10000>;
			status = "disabled";
		};
	};

	mbox_sfh2ap: mailbox@8090000 {
		compatible = "cix,sky1-mbox";
		reg = <0x0 0x08090000 0x0 0x10000>;
		interrupts = <GIC_SPI 391 IRQ_TYPE_LEVEL_HIGH>;
		#mbox-cells = <1>;
		cix,mbox_dir = <1>; /* 0:tx; 1:rx */
		status = "okay";
	};

	mbox_ap2sfh: mailbox@80a0000 {
		compatible = "cix,sky1-mbox";
		reg = <0x0 0x080a0000 0x0 0x10000>;
		interrupts = <GIC_SPI 392 IRQ_TYPE_LEVEL_HIGH>;
		#mbox-cells = <1>;
		cix,mbox_dir = <0>; /* 0:tx; 1:rx */
		status = "okay";
	};

	mbox_ap2pm: mailbox@6590000 {
		compatible = "cix,sky1-mbox";
		reg = <0x0 0x06590000 0x0 0x10000>;
		interrupts = <GIC_SPI 363 IRQ_TYPE_LEVEL_HIGH>;
		#mbox-cells = <1>;
		cix,mbox_dir = <0>; /* 0:tx; 1:rx */
		status = "disabled";
	};

	mbox_pm2ap: mailbox@65a0000 {
		compatible = "cix,sky1-mbox";
		reg = <0x0 0x065a0000 0x0 0x10000>;
		interrupts = <GIC_SPI 359 IRQ_TYPE_LEVEL_HIGH>;
		#mbox-cells = <1>;
		cix,mbox_dir = <1>; /* 0:tx; 1:rx */
		status = "disabled";
	};

	mbox_ap2se: mailbox@5060000 {
		compatible = "cix,sky1-mbox";
		reg = <0x0 0x05060000 0x0 0x10000>;
		interrupts = <GIC_SPI 378 IRQ_TYPE_LEVEL_HIGH>;
		#mbox-cells = <1>;
		cix,mbox_dir = <0>; /* 0:tx; 1:rx */
		status = "disabled";
	};

	mbox_se2ap: mailbox@5070000 {
		compatible = "cix,sky1-mbox";
		reg = <0x0 0x05070000 0x0 0x10000>;
		interrupts = <GIC_SPI 379 IRQ_TYPE_LEVEL_HIGH>;
		#mbox-cells = <1>;
		cix,mbox_dir = <1>; /* 0:tx; 1:rx */
		status = "disabled";
	};

	ap2pm_scmi_mem: ap2pm-shmem@0 {
		compatible = "arm,scmi-shmem";
		#address-cells = <2>;
		#size-cells = <2>;
		reg = <0x0 0x06590000 0x0 0x80>;
		status = "disabled";
	};

	pm2ap_scmi_mem: pm2pm-shmem@0 {
		compatible = "arm,scmi-shmem";
		#address-cells = <2>;
		#size-cells = <2>;
		reg = <0x0 0x065a0000 0x0 0x80>;
		status = "disabled";
	};

	ap_tfa_scmi_mem: ap2tf-shmem@1 {
		compatible = "arm,scmi-shmem";
		reg = <0x0 0x84380000 0x0 0x80>;
		status = "disabled";
	};

	firmware {
		ap_to_pm_scmi: scmi {
			compatible = "arm,scmi";
			mbox-names = "tx", "rx";
			mboxes = <&mbox_ap2pm 8>, /*index=8: Reg/DB base channel*/
				 <&mbox_pm2ap 8>;
			shmem = <&ap2pm_scmi_mem &pm2ap_scmi_mem>;
			#address-cells = <1>;
			#size-cells = <0>;
			status = "disabled";

			scmi_dvfs: protocol@13 {
				reg = <0x13>;
				#clock-cells = <1>;
				#power-domain-cells = <1>;
			};

			scmi_clk: protocol@14 {
				reg = <0x14>;
				#clock-cells = <1>;
			};

			scmi_sensor: protocol@15 {
				reg = <0x15>;
				#thermal-sensor-cells = <1>;
			};

			scmi_pm_excp: protocol@81 {
				reg = <0x81>;
			};
		};

		ap_to_tfa_scmi:scmi-smc {
			compatible = "arm,scmi-smc";
			arm,smc-id = <0xc2000001>;
			#address-cells = <1>;
			#size-cells = <0>;
			shmem = <&ap_tfa_scmi_mem>;
			status = "disabled";

			smc_devpd: protocol@11 {
				reg = <0x11>;
				#power-domain-cells = <1>;
			};
		};

		sdei: sdei-smc {
			compatible	= "arm,sdei-1.0";
			method		= "smc";
			status		= "okay";
		};

		optee: optee {
			compatible	= "linaro,optee-tz";
			method		= "smc";
		};
	};

	armcb_config: armcb_config {
		compatible = "armcb,sky1-config-i7";
		interrupts = <GIC_SPI 328 IRQ_TYPE_LEVEL_HIGH>,
				<GIC_SPI 329 IRQ_TYPE_LEVEL_HIGH>;
		status = "disabled";
	};

	cix_vi_hw: cix_vi_hw {
		compatible = "cix,cix-vi-hw";
		clocks = <&scmi_clk CLK_TREE_CSI_PHY0_PSM>,
				<&scmi_clk CLK_TREE_CSI_PHY0_APBCLK>,
				<&scmi_clk CLK_TREE_CSI_PHY1_PSM>,
				<&scmi_clk CLK_TREE_CSI_PHY1_APBCLK>,
				<&scmi_clk CLK_TREE_CSI_CTRL0_PCLK>,
				<&scmi_clk CLK_TREE_CSI_CTRL0_SYSCLK>,
				<&scmi_clk CLK_TREE_CSI_CTRL0_PIXEL0_CLK>,
				<&scmi_clk CLK_TREE_CSI_CTRL0_PIXEL1_CLK>,
				<&scmi_clk CLK_TREE_CSI_CTRL0_PIXEL2_CLK>,
				<&scmi_clk CLK_TREE_CSI_CTRL0_PIXEL3_CLK>,
				<&scmi_clk CLK_TREE_CSI_CTRL1_PCLK>,
				<&scmi_clk CLK_TREE_CSI_CTRL1_SYSCLK>,
				<&scmi_clk CLK_TREE_CSI_CTRL1_PIXEL0_CLK>,
				<&scmi_clk CLK_TREE_CSI_CTRL2_PCLK>,
				<&scmi_clk CLK_TREE_CSI_CTRL2_SYSCLK>,
				<&scmi_clk CLK_TREE_CSI_CTRL2_PIXEL0_CLK>,
				<&scmi_clk CLK_TREE_CSI_CTRL2_PIXEL1_CLK>,
				<&scmi_clk CLK_TREE_CSI_CTRL2_PIXEL2_CLK>,
				<&scmi_clk CLK_TREE_CSI_CTRL2_PIXEL3_CLK>,
				<&scmi_clk CLK_TREE_CSI_CTRL3_PCLK>,
				<&scmi_clk CLK_TREE_CSI_CTRL3_SYSCLK>,
				<&scmi_clk CLK_TREE_CSI_CTRL3_PIXEL0_CLK>,
				<&scmi_clk CLK_TREE_CSI_DMA0_PCLK>,
				<&scmi_clk CLK_TREE_CSI_DMA1_PCLK>,
				<&scmi_clk CLK_TREE_CSI_DMA2_PCLK>,
				<&scmi_clk CLK_TREE_CSI_DMA3_PCLK>;
		clock-names = "phy0_psmclk", "phy0_apbclk",
					"phy1_psmclk", "phy1_apbclk",
					"csi0_pclk", "csi0_sclk", "csi0_p0clk",
					"csi0_p1clk", "csi0_p2clk", "csi0_p3clk",
					"csi1_pclk", "csi1_sclk", "csi1_p0clk",
					"csi2_pclk", "csi2_sclk", "csi2_p0clk",
					"csi2_p1clk", "csi2_p2clk", "csi2_p3clk",
					"csi3_pclk", "csi3_sclk", "csi3_p0clk",
					"dma0_pclk", "dma1_pclk",
					"dma2_pclk", "dma3_pclk";

		resets = <&src SKY1_CSIDPHY_PRST0_N>,
				<&src SKY1_CSIDPHY_CMNRST0_N>,
				<&src SKY1_CSIDPHY_PRST1_N>,
				<&src SKY1_CSIDPHY_CMNRST1_N>,
				<&src SKY1_CSI_RCSU0_RESET_N>,
				<&src SKY1_CSI_RCSU1_RESET_N>,
				<&src SKY1_CSI0_RST_N>,
				<&src SKY1_CSI1_RST_N>,
				<&src SKY1_CSI2_RST_N>,
				<&src SKY1_CSI3_RST_N>,
				<&src SKY1_CSIBRDGE0_RST_N>,
				<&src SKY1_CSIBRDGE1_RST_N>,
				<&src SKY1_CSIBRDGE2_RST_N>,
				<&src SKY1_CSIBRDGE3_RST_N>;

		reset-names = "phy0_prst", "phy0_cmnrst",
					"phy1_prst", "phy1_cmnrst",
					"rcsu0_reset", "rcsu1_reset",
					"csi0_reset", "csi1_reset",
					"csi2_reset", "csi3_reset",
					"csibridge0_reset",
					"csibridge1_reset",
					"csibridge2_reset",
					"csibridge3_reset";
		ahb-dphy0-base = <0x142A0000>;
		ahb-dphy0-size = <0x10000>;
		ahb-dphy1-base = <0x14300000>;
		ahb-dphy1-size = <0x10000>;
		ahb-csi0-base = <0x14280000>;
		ahb-csi0-size = <0x10000>;
		ahb-csi1-base = <0x14290000>;
		ahb-csi1-size = <0x10000>;
		ahb-csi2-base = <0x142E0000>;
		ahb-csi2-size = <0x10000>;
		ahb-csi3-base = <0x142F0000>;
		ahb-csi3-size = <0x10000>;
		ahb-csidma0-base = <0x142B0000>;
		ahb-csidma0-size = <0x10000>;
		ahb-csidma1-base = <0x142C0000>;
		ahb-csidma1-size = <0x10000>;
		ahb-csidma2-base = <0x14310000>;
		ahb-csidma2-size = <0x10000>;
		ahb-csidma3-base = <0x14320000>;
		ahb-csidma3-size = <0x10000>;
		ahb-csircsu0-base = <0x14270000>;
		ahb-csircsu0-size = <0x10000>;
		ahb-csircsu1-base = <0x142D0000>;
		ahb-csircsu1-size = <0x10000>;
		interrupts =<GIC_SPI 452 IRQ_TYPE_LEVEL_HIGH>,
				<GIC_SPI 453 IRQ_TYPE_LEVEL_HIGH>,
				<GIC_SPI 454 IRQ_TYPE_LEVEL_HIGH>,
				<GIC_SPI 455 IRQ_TYPE_LEVEL_HIGH>,
				<GIC_SPI 456 IRQ_TYPE_LEVEL_HIGH>,
				<GIC_SPI 457 IRQ_TYPE_LEVEL_HIGH>,
				<GIC_SPI 458 IRQ_TYPE_LEVEL_HIGH>,
				<GIC_SPI 459 IRQ_TYPE_LEVEL_HIGH>;
		status = "disabled";
	};

	armcb_ispmem: armcb_ispmem {
		compatible = "armcb,isp-mem";
		power-domains = <&smc_devpd SKY1_PD_ISP0>;
		power-domain-names = "pd_isp0";
		clocks = <&scmi_clk CLK_TREE_ISP_ACLK>,
					<&scmi_clk CLK_TREE_ISP_SCLK>;
		clock-names = "isp_aclk", "isp_sclk";
		resets = <&src SKY1_ISP_RCSU0_RESET_N>,
					<&src SKY1_ISP_SRESET_N>,
					<&src SKY1_ISP_ARESET_N>,
					<&src SKY1_ISP_HRESET_N>,
					<&src SKY1_ISP_GDCRESET_N>;
		reset-names = "rcsu_reset", "isp_sreset", "isp_areset",
						"isp_hreset", "isp_gdcreset";

		ahb-pmctrl-res-base = <0x16000404>;
		ahb-pmctrl-res-size = <0x1>;
		ahb-rcsuisp0-res-base = <0x14330000>;
		ahb-rcsuisp0-res-size = <0x1000>;
		ahb-rcsuisp1-res-base = <0x14350000>;
		ahb-rcsuisp1-res-size = <0x1000>;
		iommus = <&smmu_mmhub 0x1F>;
		status = "disabled";
	};

	reg_definition: reg-definition@05040100 {
		compatible = "sky1,csu_se_pub", "syscon";
		reg = <0x0 0x05040000 0x0 0x1000>;
	};

	sky1_rng: sky1-rng@05055300 {
		compatible = "cix,sky1-rng";
		reg = <0x0 0x05055300 0x0 0x30>;
		status = "disabled";
	};

	cix_reboot{
		compatible = "cix,reboot";
		arm,smc-id = <0xc2000002>;
		/*need to add register to record reason*/
		status = "disabled";
	};

	cix_pmu_ci700: cix_pmu_ci700 {
		compatible = "cix,pmu";
		reg = <0x00 0x0a00032c 0x00 0x4>,
			<0x00 0x0a000330 0x00 0x4>,
			<0x00 0x0a000334 0x00 0x4>,
			<0x00 0x0a00033c 0x00 0x4>;
		status = "disabled";
	};

	cix_pmu_ni700: cix_pmu_ni700 {
		compatible = "cix,pmu";
		reg = <0x00 0x0a06032c 0x00 0x4>,
			<0x00 0x0a060330 0x00 0x4>,
			<0x00 0x0a060334 0x00 0x4>,
			<0x00 0x0a06033c 0x00 0x4>;
		status = "disabled";
	};

	cix_bus_ci700: cix_bus_ci700 {
		compatible = "cix,bus-ci700";
		power-domain-names = "perf";
		power-domains = <&scmi_dvfs CI700_DFS_DOMAIN_ID>;
		devfreq-events = <&cix_pmu_ci700>;
		status = "disabled";
	};

	cix_bus_ni700: cix_bus_ni700 {
		compatible = "cix,bus-ni700";
		power-domain-names = "perf";
		power-domains = <&scmi_dvfs NI700_DFS_DOMAIN_ID>;
		devfreq-events = <&cix_pmu_ni700>;
		status = "disabled";
	};

	cix_ipa: cix_cpu_ipa {
		compatible = "cix,cpu-ipa";
		reg = <0x00 0x83bf0300 0x00 0x300>;
		status = "disabled";
	};

	cix_ddrlp: cix_ddr_lp {
		compatible = "cix,ddr-lp";
		status = "disabled";
	};

        thermal_zones:thermal-zones {
		vpu-thermal {
			polling-delay-passive = <250>;
			polling-delay = <1000>;
			thermal-sensors = <&scmi_sensor VPU_TEMP_SENSOR_ID>;

			trips {
				trip-point-0 {
					temperature = <95000>;
					hysteresis = <1000>;
					type = "passive";
				};
			};
		};

		gpu0-thermal {
			polling-delay-passive = <100>;
			polling-delay = <1000>;
			thermal-sensors = <&scmi_sensor GPU_BOTTOM_TEMP_SENSOR_ID>;

			trips {
				trip-point-0 {
					temperature = <95000>;
					hysteresis = <1000>;
					type = "passive";
				};
			};
		};

		gpu1-thermal {
			polling-delay-passive = <100>;
			polling-delay = <1000>;
			thermal-sensors = <&scmi_sensor GPU_TOP_TEMP_SENSOR_ID>;

			trips {
				trip-point-0 {
					temperature = <95000>;
					hysteresis = <1000>;
					type = "passive";
				};
			};
		};

		brc-thermal {
			polling-delay-passive = <250>;
			polling-delay = <1000>;
			thermal-sensors = <&scmi_sensor SOC_BRC_TEMP_SENSOR_ID>;

			trips {
				trip-point-0 {
					temperature = <95000>;
					hysteresis = <1000>;
					type = "passive";
				};
			};
		};

		ddr0-thermal {
			polling-delay-passive = <250>;
			polling-delay = <1000>;
			thermal-sensors = <&scmi_sensor DDR_BOTTOM4_TEMP_SENSOR_ID>;

			trips {
				trip-point-0 {
					temperature = <95000>;
					hysteresis = <1000>;
					type = "passive";
				};
			};
		};

		ddr1-thermal {
			polling-delay-passive = <250>;
			polling-delay = <1000>;
			thermal-sensors = <&scmi_sensor DDR_TOP_TEMP_SENSOR_ID>;

			trips {
				trip-point-0 {
					temperature = <95000>;
					hysteresis = <1000>;
					type = "passive";
				};
			};
		};

		ci700-thermal {
			polling-delay-passive = <250>;
			polling-delay = <1000>;
			thermal-sensors = <&scmi_sensor CI700_TEMP_SENSOR_ID>;

			trips {
				trip-point-0 {
					temperature = <95000>;
					hysteresis = <1000>;
					type = "passive";
				};
			};
		};

		npu-thermal {
			polling-delay-passive = <250>;
			polling-delay = <1000>;
			thermal-sensors = <&scmi_sensor NPU_TEMP_SENSOR_ID>;

			trips {
				trip-point-0 {
					temperature = <95000>;
					hysteresis = <1000>;
					type = "passive";
				};
			};
		};

		trc-thermal {
			polling-delay-passive = <250>;
			polling-delay = <1000>;
			thermal-sensors = <&scmi_sensor SOC_TRC_TEMP_SENSOR_ID>;

			trips {
				trip-point-0 {
					temperature = <95000>;
					hysteresis = <1000>;
					type = "passive";
				};
			};
		};

		gpu-avg-thermal {
			polling-delay-passive = <100>;
			polling-delay = <1000>;
			thermal-sensors = <&scmi_sensor GPU_AVERAGE_TEMP_SENSOR_ID>;
			sustainable-power = <15000>;

			trips {
				switch_on:trip-point-0 {
					temperature = <70000>;
					hysteresis = <1000>;
					type = "passive";
				};

				target_on:trip-point-1 {
					temperature = <85000>;
					hysteresis = <1000>;
					type = "passive";
				};
			};

			cooling-maps {
				map0 {
					trip = <&switch_on>;
					cooling-device = <&gpu THERMAL_NO_LIMIT THERMAL_NO_LIMIT>;
				};
				map1 {
					trip = <&target_on>;
					cooling-device = <&gpu THERMAL_NO_LIMIT THERMAL_NO_LIMIT>;
				};
			};
		};
        };

	cix_dst: cix_dst {
		compatible = "cix,dst", "simple-bus";
		ramlog_addr = <0x0 0x83DA0000>;
		ramlog_size = <0x0 0x00040000>;
		memory-region = <&rdr_res_region>;
		rdr-log-max-size = <0x800000>;
		rdr_area_num = <15>;
		rdr_area_sizes = <0x100000 0x10000 0x10000 0x10000 0x10000 0x10000
				0x10000 0x10000 0x10000 0x10000 0x10000 0x10000
				0x10000 0x10000 0x10000>;
		rdr-log-max-nums = <6>;
		wait-dumplog-timeout = <1000>;
		unexpected-max-reboot-times = <1>;
		rdr-dumpctl="1111111111";
		status = "disabled";

		exception_trace: exception_trace {
			compatible = "rdr,exceptiontrace";
			area_num = <1>;
			area_sizes = < 0x1000 >;
			status = "disabled";
		};

		ap_adapter: ap_adapter{
			compatible = "rdr,rdr_ap_adapter";
			/* reg-dump-regions = <3>; */
			/* reg = <0 0x61080000 0 0x10000>, */
			/*      <0 0x61090000 0 0x10000>, */
			/*      <0 0x610a0000 0 0x10000>; */
			/* reg-names = "test1", "test2", "test3"; */
			ap_trace_irq_size = <0x10000>;
			ap_trace_task_size = <0x10000>;
			ap_trace_cpu_idle_size = <0x10000>;
			ap_trace_worker_size = <0x10000>;
			ap_trace_time_size = <0x10000>;
			ap_trace_cpu_on_off_size = <0x10000>;
			ap_trace_syscall_size = <0x10000>;
			ap_trace_hung_task_size = <0x10000>;
			ap_trace_tasklet_size = <0x10000>;
			ap_dump_mem_modu_test_size = <1024>;
			ap_dump_mem_modu_idm_size = <0x1000>;
			ap_dump_mem_modu_tzc400_size = <0x1000>;
			ap_dump_mem_modu_smmu_size = <0x1000>;
			ap_dump_mem_modu_tfa_size = <0x4000>;
			ap_dump_mem_modu_gap_size = <256>;
			ap_log_console_size = <0xc000>;
			ap_log_dmesg_size = <0xc000>;
			status = "disabled";
		};
	};

	ddr_ctrl0: ddr_ctrl@0C010000 {
		compatible = "cadence,ddr_ctrl";
		reg = <0x0 0x0C010000 0x0 0x20000>,
			<0x0 0x83c00000 0x0 0x1000>;
		interrupts = <GIC_SPI 207 IRQ_TYPE_LEVEL_HIGH>;
		channel_id = <0x0>;
		status = "disabled";
	};

	ddr_ctrl1: ddr_ctrl@0C030000 {
		compatible = "cadence,ddr_ctrl";
		reg = <0x0 0x0C030000 0x0 0x20000>,
			<0x0 0x83c00000 0x0 0x1000>;
		interrupts = <GIC_SPI 210 IRQ_TYPE_LEVEL_HIGH>;
		channel_id = <0x1>;
		status = "disabled";
	};

	ddr_ctrl2: ddr_ctrl@0C050000 {
		compatible = "cadence,ddr_ctrl";
		reg = <0x0 0x0C050000 0x0 0x20000>,
			<0x0 0x83c00000 0x0 0x1000>;
		interrupts = <GIC_SPI 213 IRQ_TYPE_LEVEL_HIGH>;
		channel_id = <0x2>;
		status = "disabled";
	};

	ddr_ctrl3: ddr_ctrl@0C070000 {
		compatible = "cadence,ddr_ctrl";
		reg = <0x0 0x0C070000 0x0 0x20000>,
			<0x0 0x83c00000 0x0 0x1000>;
		interrupts = <GIC_SPI 216 IRQ_TYPE_LEVEL_HIGH>;
		channel_id = <0x3>;
		status = "disabled";
	};

#ifdef SKY1_CORESIGHT_SUPPORT
	ete0: ete0 {
		compatible = "arm,embedded-trace-extension";
		cpu = <&CPU0>;
		status = "okay";
#ifndef SKY1_CORESIGHT_TRBE_SUPPORT
		out-ports {
			port {
				ete_out_port0: endpoint {
					remote-endpoint = <&dsu_funnel_in_port0>;
				};
			};
		};
#endif
	};

	ete1: ete1 {
		compatible = "arm,embedded-trace-extension";
		cpu = <&CPU1>;
		status = "okay";

#ifndef SKY1_CORESIGHT_TRBE_SUPPORT
		out-ports {
			port {
				ete_out_port1: endpoint {
					remote-endpoint = <&dsu_funnel_in_port1>;
				};
			};
		};
#endif
	};

	ete2: ete2 {
		compatible = "arm,embedded-trace-extension";
		cpu = <&CPU2>;
		status = "okay";

#ifndef SKY1_CORESIGHT_TRBE_SUPPORT
		out-ports {
			port {
				ete_out_port2: endpoint {
					remote-endpoint = <&dsu_funnel_in_port2>;
				};
			};
		};
#endif
	};

	ete3: ete3 {
		compatible = "arm,embedded-trace-extension";
		cpu = <&CPU3>;
		status = "okay";

#ifndef SKY1_CORESIGHT_TRBE_SUPPORT
		out-ports {
			port {
				ete_out_port3: endpoint {
					remote-endpoint = <&dsu_funnel_in_port3>;
				};
			};
		};
#endif
	};

	ete4: ete4 {
		compatible = "arm,embedded-trace-extension";
		cpu = <&CPU4>;
		status = "okay";

#ifndef SKY1_CORESIGHT_TRBE_SUPPORT
		out-ports {
			port {
				ete_out_port4: endpoint {
					remote-endpoint = <&dsu_funnel_in_port4>;
				};
			};
		};
#endif
	};

	ete5: ete5 {
		compatible = "arm,embedded-trace-extension";
		cpu = <&CPU5>;
		status = "okay";

#ifndef SKY1_CORESIGHT_TRBE_SUPPORT
		out-ports {
			port {
				ete_out_port5: endpoint {
					remote-endpoint = <&dsu_funnel_in_port5>;
				};
			};
		};
#endif
	};

	ete6: ete6 {
		compatible = "arm,embedded-trace-extension";
		cpu = <&CPU6>;
		status = "okay";

#ifndef SKY1_CORESIGHT_TRBE_SUPPORT
		out-ports {
			port {
				ete_out_port6: endpoint {
					remote-endpoint = <&dsu_funnel_in_port6>;
				};
			};
		};
#endif
	};

	ete7: ete7 {
		compatible = "arm,embedded-trace-extension";
		cpu = <&CPU7>;
		status = "okay";

#ifndef SKY1_CORESIGHT_TRBE_SUPPORT
		out-ports {
			port {
				ete_out_port7: endpoint {
					remote-endpoint = <&dsu_funnel_in_port7>;
				};
			};
		};
#endif
	};

	ete8: ete8 {
		compatible = "arm,embedded-trace-extension";
		cpu = <&CPU8>;
		status = "okay";

#ifndef SKY1_CORESIGHT_TRBE_SUPPORT
		out-ports {
			port {
				ete_out_port8: endpoint {
					remote-endpoint = <&dsu_funnel_in_port8>;
				};
			};
		};
#endif
	};

	ete9: ete9 {
		compatible = "arm,embedded-trace-extension";
		cpu = <&CPU9>;
		status = "okay";

#ifndef SKY1_CORESIGHT_TRBE_SUPPORT
		out-ports {
			port {
				ete_out_port9: endpoint {
					remote-endpoint = <&dsu_funnel_in_port9>;
				};
			};
		};
#endif
	};

	ete10: ete10 {
		compatible = "arm,embedded-trace-extension";
		cpu = <&CPU10>;
		status = "okay";

#ifndef SKY1_CORESIGHT_TRBE_SUPPORT
		out-ports {
			port {
				ete_out_port10: endpoint {
					remote-endpoint = <&dsu_funnel_in_port10>;
				};
			};
		};
#endif
	};

	ete11: ete11 {
		compatible = "arm,embedded-trace-extension";
		cpu = <&CPU11>;
		status = "okay";

#ifndef SKY1_CORESIGHT_TRBE_SUPPORT
		out-ports {
			port {
				ete_out_port11: endpoint {
					remote-endpoint = <&dsu_funnel_in_port11>;
				};
			};
		};
#endif
	};

#ifndef SKY1_CORESIGHT_TRBE_SUPPORT
	funnel_dsu: funnel@dsu {
		compatible = "arm,coresight-static-funnel";
		status = "okay";

		in-ports {
			#address-cells = <1>;
			#size-cells = <0>;

			port@0 {
				reg = <0>;
				dsu_funnel_in_port0: endpoint {
					remote-endpoint = <&ete_out_port0>;
				};
			};

			port@1 {
				reg = <1>;
				dsu_funnel_in_port1: endpoint {
					remote-endpoint = <&ete_out_port1>;
				};
			};

			port@2 {
				reg = <2>;
				dsu_funnel_in_port2: endpoint {
					remote-endpoint = <&ete_out_port2>;
				};
			};

			port@3 {
				reg = <3>;
				dsu_funnel_in_port3: endpoint {
					remote-endpoint = <&ete_out_port3>;
				};
			};

			port@4 {
				reg = <4>;
				dsu_funnel_in_port4: endpoint {
					remote-endpoint = <&ete_out_port4>;
				};
			};

			port@5 {
				reg = <5>;
				dsu_funnel_in_port5: endpoint {
					remote-endpoint = <&ete_out_port5>;
				};
			};

			port@6 {
				reg = <6>;
				dsu_funnel_in_port6: endpoint {
					remote-endpoint = <&ete_out_port6>;
				};
			};

			port@7 {
				reg = <7>;
				dsu_funnel_in_port7: endpoint {
					remote-endpoint = <&ete_out_port7>;
				};
			};

			port@8 {
				reg = <8>;
				dsu_funnel_in_port8: endpoint {
					remote-endpoint = <&ete_out_port8>;
				};
			};

			port@9 {
				reg = <9>;
				dsu_funnel_in_port9: endpoint {
					remote-endpoint = <&ete_out_port9>;
				};
			};

			port@10 {
				reg = <10>;
				dsu_funnel_in_port10: endpoint {
					remote-endpoint = <&ete_out_port10>;
				};
			};

			port@11 {
				reg = <11>;
				dsu_funnel_in_port11: endpoint {
					remote-endpoint = <&ete_out_port11>;
				};
			};
		};

		out-ports {
			port {
				dsu_funnel_out_port: endpoint {
					remote-endpoint = <&cpu_etf_in_port>;
				};
			};
		};
	};

	etf_cpu: etf@cpu {
		compatible = "arm,coresight-tmc", "arm,primecell";
		reg = <0x0 0x18060000 0x0 0x10000>;
		arm,primecell-periphid = <0x000bb9ea>;
		clocks = <&dfd_clk>;
		clock-names = "apb_pclk";
		status = "okay";

		in-ports {
			port {
				cpu_etf_in_port: endpoint {
					remote-endpoint = <&dsu_funnel_out_port>;
				};
			};
		};

		out-ports {
			port {
				cpu_etf_out_port: endpoint {
					remote-endpoint = <&soc_funnel_in_port2>;
				};
			};
		};
	};

	stm: stm@18010000 {
		compatible = "arm,coresight-stm", "arm,primecell";
		reg =	<0 0x18010000 0 0x10000>,
				<0x0000001C 0xB0000000 0 0x1000000>;
		reg-names = "stm-base", "stm-stimulus-base";
		arm,primecell-periphid = <0x000bb963>;
		clocks = <&dfd_clk>;
		clock-names = "apb_pclk";
		status = "okay";

		out-ports {
			port {
				stm0_out_port: endpoint {
					remote-endpoint = <&stm_etf_in_port>;
				};
			};
		};
	};

	etf_stm: etf@stm {
		compatible = "arm,coresight-tmc", "arm,primecell";
		reg = <0x0 0x180A0000 0x0 0x10000>;
		arm,primecell-periphid = <0x000bb9ea>;
		clocks = <&dfd_clk>;
		clock-names = "apb_pclk";
		status = "okay";

		in-ports {
			port {
				stm_etf_in_port: endpoint {
					remote-endpoint = <&stm0_out_port>;
				};
			};
		};

		out-ports {
			port {
				stm_etf_out_port: endpoint {
					remote-endpoint = <&soc_funnel_in_port6>;
				};
			};
		};
	};

	funnel_soc: funnel@soc {
		compatible = "arm,coresight-dynamic-funnel", "arm,primecell";
		reg = <0x0 0x180B0000 0x0 0x10000>;
		arm,primecell-periphid = <0x000bb9eb>;
		clocks = <&dfd_clk>;
		clock-names = "apb_pclk";
		status = "okay";

		in-ports {
			#address-cells = <1>;
			#size-cells = <0>;

			port@2 {
				reg = <2>;
				soc_funnel_in_port2: endpoint {
					remote-endpoint = <&cpu_etf_out_port>;
				};
			};

			port@6 {
				reg = <6>;
				soc_funnel_in_port6: endpoint {
					remote-endpoint = <&stm_etf_out_port>;
				};
			};

		};

		out-ports {
			port {
				soc_funnel_out_port: endpoint {
					remote-endpoint = <&soc_etf_in_port>;
				};
			};
		};
	};

	etf_soc: etf@soc {
		compatible = "arm,coresight-tmc", "arm,primecell";
		reg = <0x0 0x19000000 0x0 0x10000>;
		arm,primecell-periphid = <0x000bb9ea>;
		clocks = <&dfd_clk>;
		clock-names = "apb_pclk";
		status = "okay";

		in-ports {
			port {
				soc_etf_in_port: endpoint {
					remote-endpoint = <&soc_funnel_out_port>;
				};
			};
		};

		out-ports {
			port {
				soc_etf_out_port: endpoint {
					remote-endpoint = <&etr_in_port>;
				};
			};
		};
	};

	etr0: etr@180c0000 {
		compatible = "arm,coresight-tmc", "arm,primecell";
		reg = <0x0 0x180c0000 0x0 0x10000>;
		arm,primecell-periphid = <0x000bb9e8>;
		clocks = <&dfd_clk>;
		clock-names = "apb_pclk";
		status = "okay";

		in-ports {
			port {
				etr_in_port: endpoint {
					remote-endpoint = <&soc_etf_out_port>;
				};
			};
		};

		out-ports {
			port {
				etr_out_port: endpoint {
					remote-endpoint = <&catu_in_port>;
				};
			};
		};
	};

	catu0: catu@180d0000 {
		compatible = "arm,coresight-catu", "arm,primecell";
		reg = <0 0x180d0000 0 0x10000>;
		/* interrupts = <GIC_SPI 4 IRQ_TYPE_LEVEL_HIGH>; */
		arm,primecell-periphid = <0x000bb9ee>;
		clocks = <&dfd_clk>;
		clock-names = "apb_pclk";
		status = "okay";

		in-ports {
			port {
				catu_in_port: endpoint {
					remote-endpoint = <&etr_out_port>;
				};
			};
		};
	};
#endif

#ifdef SKY1_CORESIGHT_TRBE_SUPPORT
	trbe {
		compatible = "arm,trace-buffer-extension";
		interrupts = <GIC_PPI 2 IRQ_TYPE_LEVEL_LOW>;
		interrupt-parent = <&gic>;
		status = "okay";
	};
#endif
#endif
};

